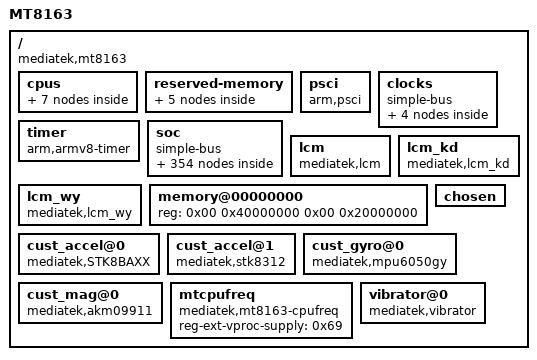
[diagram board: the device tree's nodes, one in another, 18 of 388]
/dts-v1/;

/ {
	model = "MT8163";
	compatible = "mediatek,mt8163";
	interrupt-parent = < 0x01 >;
	#address-cells = < 0x02 >;
	#size-cells = < 0x02 >;

	cpus {
		#address-cells = < 0x01 >;
		#size-cells = < 0x00 >;

		cpu@0 {
			device_type = "cpu";
			compatible = "arm,cortex-a53";
			reg = < 0x00 >;
			enable-method = "mt-boot";
			cpu-idle-states = < 0x02 0x02 0x03 0x03 0x03 >;
			cpu-release-addr = < 0x00 0x40000200 >;
			clock-frequency = "M|m";
		};

		cpu@1 {
			device_type = "cpu";
			compatible = "arm,cortex-a53";
			reg = < 0x01 >;
			enable-method = "mt-boot";
			cpu-idle-states = < 0x02 0x02 0x03 0x03 0x03 >;
			cpu-release-addr = < 0x00 0x40000200 >;
			clock-frequency = "M|m";
		};

		cpu@2 {
			device_type = "cpu";
			compatible = "arm,cortex-a53";
			reg = < 0x02 >;
			enable-method = "mt-boot";
			cpu-idle-states = < 0x02 0x02 0x03 0x03 0x03 >;
			cpu-release-addr = < 0x00 0x40000200 >;
			clock-frequency = "M|m";
		};

		cpu@3 {
			device_type = "cpu";
			compatible = "arm,cortex-a53";
			reg = < 0x03 >;
			enable-method = "mt-boot";
			cpu-idle-states = < 0x02 0x02 0x03 0x03 0x03 >;
			cpu-release-addr = < 0x00 0x40000200 >;
			clock-frequency = "M|m";
		};

		idle-states {
			entry-method = "arm,psci";

			cpu-sleep-0-0 {
				compatible = "arm,idle-state";
				arm,psci-suspend-param = < 0x10000 >;
				entry-latency-us = < 0x258 >;
				exit-latency-us = < 0x258 >;
				min-residency-us = < 0x4b0 >;
				linux,phandle = < 0x03 >;
				phandle = < 0x03 >;
			};

			cluster-sleep-0 {
				compatible = "arm,idle-state";
				arm,psci-suspend-param = < 0x2010000 >;
				entry-latency-us = < 0x320 >;
				exit-latency-us = < 0x3e8 >;
				min-residency-us = < 0x7d0 >;
				linux,phandle = < 0x02 >;
				phandle = < 0x02 >;
			};
		};
	};

	reserved-memory {
		#address-cells = < 0x02 >;
		#size-cells = < 0x02 >;
		ranges;

		atf-reserved-memory@43000000 {
			compatible = "mediatek,mt8163-atf-reserved-memory";
			no-map;
			reg = < 0x00 0x43000000 0x00 0x30000 >;
		};

		ram_console-reserved-memory@44400000 {
			compatible = "mediatek,ram_console";
			reg = < 0x00 0x44400000 0x00 0x10000 >;
		};

		pstore-reserved-memory@44410000 {
			compatible = "mediatek,pstore";
			reg = < 0x00 0x44410000 0x00 0xe0000 >;
		};

		minirdump-reserved-memory@444f0000 {
			compatible = "mediatek,minirdump";
			reg = < 0x00 0x444f0000 0x00 0x10000 >;
		};

		consys-reserve-memory {
			compatible = "mediatek,consys-reserve-memory";
			no-map;
			size = < 0x00 0x200000 >;
			alignment = < 0x00 0x200000 >;
		};
	};

	psci {
		compatible = "arm,psci";
		method = "smc";
		cpu_suspend = < 0x84000001 >;
		cpu_off = < 0x84000002 >;
		cpu_on = < 0x84000003 >;
		affinity_info = < 0x84000004 >;
	};

	clocks {
		#address-cells = < 0x02 >;
		#size-cells = < 0x02 >;
		compatible = "simple-bus";
		ranges;

		clk_null {
			compatible = "fixed-clock";
			#clock-cells = < 0x00 >;
			clock-frequency = < 0x00 >;
			linux,phandle = < 0x35 >;
			phandle = < 0x35 >;
		};

		clk26m {
			compatible = "fixed-clock";
			#clock-cells = < 0x00 >;
			clock-frequency = < 0x18cba80 >;
			linux,phandle = < 0x09 >;
			phandle = < 0x09 >;
		};

		clk32k {
			compatible = "fixed-clock";
			#clock-cells = < 0x00 >;
			clock-frequency = < 0x7d00 >;
		};

		dummy26m {
			compatible = "fixed-clock";
			clock-frequency = < 0x18cba80 >;
			#clock-cells = < 0x00 >;
		};
	};

	timer {
		compatible = "arm,armv8-timer";
		interrupt-parent = < 0x04 >;
		interrupts = < 0x01 0x0d 0xf08 0x01 0x0e 0xf08 0x01 0x0b 0xf08 0x01 0x0a 0xf08 >;
		clock-frequency = < 0xc65d40 >;
	};

	soc {
		#address-cells = < 0x02 >;
		#size-cells = < 0x02 >;
		compatible = "simple-bus";
		ranges;

		chipid@08000000 {
			compatible = "mediatek,mt8163-chipid";
			reg = < 0x00 0x8000000 0x00 0x10 >;
		};

		topckgen@10000000 {
			compatible = "mediatek,mt8163-topckgen";
			reg = < 0x00 0x10000000 0x00 0x1000 >;
			#clock-cells = < 0x01 >;
			linux,phandle = < 0x06 >;
			phandle = < 0x06 >;
		};

		infracfg@10001000 {
			compatible = "mediatek,mt8163-infracfg\0syscon";
			reg = < 0x00 0x10001000 0x00 0x1000 >;
			#clock-cells = < 0x01 >;
			#reset-cells = < 0x01 >;
			linux,phandle = < 0x05 >;
			phandle = < 0x05 >;
		};

		syscfg_pctl_a@10005000 {
			compatible = "mediatek,mt8163-pctl-a-syscfg\0syscon";
			reg = < 0x00 0x10005000 0x00 0x1000 >;
			linux,phandle = < 0x07 >;
			phandle = < 0x07 >;
		};

		toprgu@10007000 {
			compatible = "mediatek,mt8163-rgu";
			reg = < 0x00 0x10007000 0x00 0x1000 >;
			interrupts = < 0x00 0x80 0x02 >;
			#reset-cells = < 0x01 >;
			linux,phandle = < 0x50 >;
			phandle = < 0x50 >;
		};

		apxgpt@10008000 {
			compatible = "mediatek,mt8163-apxgpt";
			reg = < 0x00 0x10008000 0x00 0x1000 >;
			interrupts = < 0x00 0x98 0x08 >;
			clocks = < 0x05 0x06 0x05 0x46 0x06 0x60 >;
			clock-names = "bus\0clk13m\0rtc_sel";
		};

		pinctrl@10005000 {
			compatible = "mediatek,mt8163-pinctrl";
			reg = < 0x00 0x1000b000 0x00 0x1000 >;
			mediatek,pctl-regmap = < 0x07 >;
			pins-are-numbered;
			gpio-controller;
			#gpio-cells = < 0x02 >;
			interrupt-controller;
			#interrupt-cells = < 0x02 >;
			interrupts = < 0x00 0x99 0x04 0x00 0x9a 0x04 0x00 0x9b 0x04 >;
			pinctrl-names = "default";
			pinctrl-0 = < 0x08 >;
			linux,phandle = < 0x0a >;
			phandle = < 0x0a >;

			spi1 {
				linux,phandle = < 0x23 >;
				phandle = < 0x23 >;

				pins_spi {
					pinmux = < 0x3501 0x3601 0x3701 0x3801 >;
					bias-disable;
				};
			};

			uart0gpiodefault {
				linux,phandle = < 0x0c >;
				phandle = < 0x0c >;
			};

			uart0_rx_set {
				linux,phandle = < 0x0d >;
				phandle = < 0x0d >;

				pins_cmd_dat {
					pinmux = < 0x4f01 >;
				};
			};

			uart0_rx_clear {
				linux,phandle = < 0x0e >;
				phandle = < 0x0e >;

				pins_cmd_dat {
					pinmux = < 0x4f00 >;
					slew-rate = < 0x01 >;
					output-high;
				};
			};

			uart0_tx_set {
				linux,phandle = < 0x0f >;
				phandle = < 0x0f >;

				pins_cmd_dat {
					pinmux = < 0x5001 >;
				};
			};

			uart0_tx_clear {
				linux,phandle = < 0x10 >;
				phandle = < 0x10 >;

				pins_cmd_dat {
					pinmux = < 0x5000 >;
					slew-rate = < 0x01 >;
					output-high;
				};
			};

			uart1gpiodefault {
				linux,phandle = < 0x11 >;
				phandle = < 0x11 >;
			};

			uart1_rx_set {
				linux,phandle = < 0x12 >;
				phandle = < 0x12 >;

				pins_cmd_dat {
					pinmux = < 0x5101 >;
				};
			};

			uart1_rx_clear {
				linux,phandle = < 0x13 >;
				phandle = < 0x13 >;

				pins_cmd_dat {
					pinmux = < 0x5100 >;
					slew-rate = < 0x01 >;
					output-high;
				};
			};

			uart1_tx_set {
				linux,phandle = < 0x14 >;
				phandle = < 0x14 >;

				pins_cmd_dat {
					pinmux = < 0x5201 >;
				};
			};

			uart1_tx_clear {
				linux,phandle = < 0x15 >;
				phandle = < 0x15 >;

				pins_cmd_dat {
					pinmux = < 0x5200 >;
					slew-rate = < 0x01 >;
					output-high;
				};
			};

			uart2gpiodefault {
				linux,phandle = < 0x16 >;
				phandle = < 0x16 >;
			};

			uart2_rx_set {
				linux,phandle = < 0x17 >;
				phandle = < 0x17 >;

				pins_cmd_dat {
					pinmux = < 0xe01 >;
				};
			};

			uart2_rx_clear {
				linux,phandle = < 0x18 >;
				phandle = < 0x18 >;

				pins_cmd_dat {
					pinmux = < 0xe00 >;
					slew-rate = < 0x01 >;
					output-high;
				};
			};

			uart2_tx_set {
				linux,phandle = < 0x19 >;
				phandle = < 0x19 >;

				pins_cmd_dat {
					pins = < 0xf01 >;
				};
			};

			uart2_tx_clear {
				linux,phandle = < 0x1a >;
				phandle = < 0x1a >;

				pins_cmd_dat {
					pinmux = < 0xf00 >;
					slew-rate = < 0x01 >;
					output-high;
				};
			};

			uart3gpiodefault {
				linux,phandle = < 0x1b >;
				phandle = < 0x1b >;
			};

			uart3_rx_set {
				linux,phandle = < 0x1c >;
				phandle = < 0x1c >;

				pins_cmd_dat {
					pinmux = < 0x1001 >;
				};
			};

			uart3_rx_clear {
				linux,phandle = < 0x1d >;
				phandle = < 0x1d >;

				pins_cmd_dat {
					pinmux = < 0x1000 >;
					slew-rate = < 0x01 >;
					output-high;
				};
			};

			uart3_tx_set {
				linux,phandle = < 0x1e >;
				phandle = < 0x1e >;

				pins_cmd_dat {
					pinmux = < 0x1101 >;
				};
			};

			uart3_tx_clear {
				linux,phandle = < 0x1f >;
				phandle = < 0x1f >;

				pins_cmd_dat {
					pinmux = < 0x1100 >;
					slew-rate = < 0x01 >;
					output-high;
				};
			};

			pinconf_default {
				linux,phandle = < 0x08 >;
				phandle = < 0x08 >;
			};

			audiodefault {
				linux,phandle = < 0x2e >;
				phandle = < 0x2e >;
			};

			eint4default {
				linux,phandle = < 0x59 >;
				phandle = < 0x59 >;
			};

			eint45 {
				linux,phandle = < 0x5a >;
				phandle = < 0x5a >;

				pins_cmd_dat {
					pins = < 0x2200 >;
					bias-disable;
				};
			};

			audexamphigh {
				linux,phandle = < 0x33 >;
				phandle = < 0x33 >;

				pins_cmd_dat {
					pins = < 0x5800 >;
					slew-rate = < 0x01 >;
					output-high;
				};
			};

			audexamplow {
				linux,phandle = < 0x34 >;
				phandle = < 0x34 >;

				pins_cmd_dat {
					pins = < 0x5800 >;
					slew-rate = < 0x01 >;
					output-low;
				};
			};

			audi2s1mode0 {
				linux,phandle = < 0x31 >;
				phandle = < 0x31 >;

				pins_cmd0_dat {
					pins = < 0x2e00 >;
				};

				pins_cmd1_dat {
					pins = < 0x2f00 >;
				};

				pins_cmd2_dat {
					pins = < 0x3000 >;
				};
			};

			audi2s1mode1 {
				linux,phandle = < 0x32 >;
				phandle = < 0x32 >;

				pins_cmd0_dat {
					pins = < 0x2e02 >;
				};

				pins_cmd1_dat {
					pins = < 0x2f02 >;
				};

				pins_cmd2_dat {
					pins = < 0x3002 >;
				};
			};

			pmicclkmode0 {
				linux,phandle = < 0x2f >;
				phandle = < 0x2f >;

				pins_cmd0_dat {
					pins = < 0x700 >;
				};

				pins_cmd1_dat {
					pins = < 0x800 >;
				};

				pins_cmd2_dat {
					pins = < 0x901 >;
				};
			};

			pmicclkmode1 {
				linux,phandle = < 0x30 >;
				phandle = < 0x30 >;

				pins_cmd0_dat {
					pins = < 0x701 >;
				};

				pins_cmd1_dat {
					pins = < 0x801 >;
				};

				pins_cmd2_dat {
					pins = < 0x901 >;
				};
			};

			cam0@0 {
				linux,phandle = < 0x48 >;
				phandle = < 0x48 >;

				pins_cmd_dat {
					pins = < 0x3500 >;
					slew-rate = < 0x01 >;
					output-low;
				};
			};

			cam0@1 {
				linux,phandle = < 0x49 >;
				phandle = < 0x49 >;

				pins_cmd_dat {
					pins = < 0x3500 >;
					slew-rate = < 0x01 >;
					output-high;
				};
			};

			cam0@2 {
				linux,phandle = < 0x4a >;
				phandle = < 0x4a >;

				pins_cmd_dat {
					pins = < 0x3800 >;
					slew-rate = < 0x01 >;
					output-low;
				};
			};

			cam0@3 {
				linux,phandle = < 0x4b >;
				phandle = < 0x4b >;

				pins_cmd_dat {
					pins = < 0x3800 >;
					slew-rate = < 0x01 >;
					output-high;
				};
			};

			cam1@0 {
				linux,phandle = < 0x4c >;
				phandle = < 0x4c >;

				pins_cmd_dat {
					pins = < 0x3500 >;
					slew-rate = < 0x01 >;
					output-low;
				};
			};

			cam1@1 {
				linux,phandle = < 0x4d >;
				phandle = < 0x4d >;

				pins_cmd_dat {
					pins = < 0x3500 >;
					slew-rate = < 0x01 >;
					output-high;
				};
			};

			cam1@2 {
				linux,phandle = < 0x4e >;
				phandle = < 0x4e >;

				pins_cmd_dat {
					pins = < 0x3600 >;
					slew-rate = < 0x01 >;
					output-low;
				};
			};

			cam1@3 {
				linux,phandle = < 0x4f >;
				phandle = < 0x4f >;

				pins_cmd_dat {
					pins = < 0x3600 >;
					slew-rate = < 0x01 >;
					output-high;
				};
			};

			camdefault {
				linux,phandle = < 0x47 >;
				phandle = < 0x47 >;

				pins_cmd_dat {
					pinmux = < 0x7701 0x6a01 0x6901 0x6701 0x6801 0x6601 0x6501 0x7001 0x6f01 0x7301 0x7401 >;
				};
			};

			default {
				linux,phandle = < 0x51 >;
				phandle = < 0x51 >;
			};

			eint0default {
				linux,phandle = < 0x5c >;
				phandle = < 0x5c >;

				pins_cmd_dat {
					pins = < 0x3300 >;
					slew-rate = < 0x00 >;
					bias-disable;
				};
			};

			eint@0 {
				linux,phandle = < 0x5d >;
				phandle = < 0x5d >;

				pins_cmd_dat {
					pins = < 0x2300 >;
					slew-rate = < 0x00 >;
					bias-disable;
				};
			};

			eintoutput0 {
				linux,phandle = < 0x5e >;
				phandle = < 0x5e >;

				pins_cmd_dat {
					pins = < 0x2300 >;
					slew-rate = < 0x01 >;
					output-low;
				};
			};

			eintoutput1 {
				linux,phandle = < 0x5f >;
				phandle = < 0x5f >;

				pins_cmd_dat {
					pins = < 0x2300 >;
					slew-rate = < 0x01 >;
					output-high;
				};
			};

			rstoutput0 {
				linux,phandle = < 0x60 >;
				phandle = < 0x60 >;

				pins_cmd_dat {
					pins = < 0x2d00 >;
					slew-rate = < 0x01 >;
					output-low;
				};
			};

			rstoutput1 {
				linux,phandle = < 0x61 >;
				phandle = < 0x61 >;

				pins_cmd_dat {
					pins = < 0x2d00 >;
					slew-rate = < 0x01 >;
					output-high;
				};
			};

			iddig_irq_init {
				linux,phandle = < 0x26 >;
				phandle = < 0x26 >;

				pins_cmd_dat {
					pins = < 0x2600 >;
					slew-rate = < 0x00 >;
					bias-pull-up = < 0x00 >;
				};
			};

			drvvbus_init {
				linux,phandle = < 0x27 >;
				phandle = < 0x27 >;

				pins_cmd_dat {
					pins = < 0x2300 >;
					slew-rate = < 0x00 >;
					bias-disable;
				};
			};

			drvvbus_low {
				linux,phandle = < 0x28 >;
				phandle = < 0x28 >;

				pins_cmd_dat {
					pins = < 0x2300 >;
					slew-rate = < 0x01 >;
					output-low;
				};
			};

			drvvbus_high {
				linux,phandle = < 0x29 >;
				phandle = < 0x29 >;

				pins_cmd_dat {
					pins = < 0x2300 >;
					slew-rate = < 0x01 >;
					output-high;
				};
			};

			pogo_init {
				linux,phandle = < 0x2a >;
				phandle = < 0x2a >;

				pins_cmd_dat {
					pins = < 0x1d00 >;
					slew-rate = < 0x00 >;
					bias-disable;
				};
			};

			pogo_low {
				linux,phandle = < 0x2b >;
				phandle = < 0x2b >;

				pins_cmd_dat {
					pins = < 0x1d00 >;
					slew-rate = < 0x01 >;
					output-low;
				};
			};

			pogo_high {
				linux,phandle = < 0x2c >;
				phandle = < 0x2c >;

				pins_cmd_dat {
					pins = < 0x1d00 >;
					slew-rate = < 0x01 >;
					output-high;
				};
			};

			gpslna@0 {
				linux,phandle = < 0x52 >;
				phandle = < 0x52 >;

				pins_cmd_dat {
					pinmux = < 0x7600 >;
					slew-rate = < 0x00 >;
					bias-disable;
					output-low;
				};
			};

			gpslna@1 {
				linux,phandle = < 0x53 >;
				phandle = < 0x53 >;

				pins_cmd_dat {
					pinmux = < 0x7600 >;
					slew-rate = < 0x01 >;
					output-high;
				};
			};

			gpslna@2 {
				linux,phandle = < 0x54 >;
				phandle = < 0x54 >;

				pins_cmd_dat {
					pinmux = < 0x7600 >;
					slew-rate = < 0x01 >;
					output-low;
				};
			};

			hdmi_pins_default {
				linux,phandle = < 0x3e >;
				phandle = < 0x3e >;

				pins_cmd_dat {
					pins = < 0x5900 >;
					slew-rate = < 0x01 >;
					bias-pull-up;
					output-high;
				};
			};

			i2c0@0 {
				linux,phandle = < 0x20 >;
				phandle = < 0x20 >;

				pins1 {
					pinmux = < 0x4b01 0x4c01 >;
					bias-disable;
				};
			};

			i2c1@0 {
				linux,phandle = < 0x21 >;
				phandle = < 0x21 >;

				pins1 {
					pinmux = < 0x3901 0x3a01 >;
					bias-disable;
				};
			};

			i2c2@0 {
				linux,phandle = < 0x22 >;
				phandle = < 0x22 >;

				pins1 {
					pinmux = < 0x4d01 0x4e01 >;
					bias-disable;
				};
			};

			lcm_gpio@83_high {
				linux,phandle = < 0x62 >;
				phandle = < 0x62 >;

				pins_cmd_dat {
					pins = < 0x5300 >;
					slew-rate = < 0x01 >;
					output-high;
				};
			};

			lcm_gpio@83_low {
				linux,phandle = < 0x63 >;
				phandle = < 0x63 >;

				pins_cmd_dat {
					pins = < 0x5300 >;
					slew-rate = < 0x01 >;
					output-low;
				};
			};

			lcm_gpio@90_high {
				linux,phandle = < 0x64 >;
				phandle = < 0x64 >;

				pins_cmd_dat {
					pins = < 0x5a00 >;
					slew-rate = < 0x01 >;
					output-high;
				};
			};

			lcm_gpio@90_low {
				linux,phandle = < 0x65 >;
				phandle = < 0x65 >;

				pins_cmd_dat {
					pins = < 0x5a00 >;
					slew-rate = < 0x01 >;
					output-low;
				};
			};

			mmc0default {
				linux,phandle = < 0x36 >;
				phandle = < 0x36 >;

				pins_cmd_dat {
					pinmux = < 0x8901 0x8801 0x8701 0x8601 0x8201 0x8101 0x8001 0x7f01 0x8401 >;
					input-enable;
					bias-pull-up;
				};

				pins_clk {
					pinmux = < 0x8501 >;
					bias-pull-down;
				};

				pins_rst {
					pinmux = < 0x8301 >;
					bias-pull-up;
				};
			};

			mmc0@0 {
				linux,phandle = < 0x37 >;
				phandle = < 0x37 >;

				pins_cmd_dat {
					pinmux = < 0x8901 0x8801 0x8701 0x8601 0x8201 0x8101 0x8001 0x7f01 0x8401 >;
					input-enable;
					drive-strength = < 0x06 >;
					bias-pull-up = < 0x65 >;
				};

				pins_clk {
					pinmux = < 0x8501 >;
					drive-strength = < 0x06 >;
					bias-pull-down = < 0x65 >;
				};

				pins_rst {
					pinmux = < 0x8301 >;
					bias-pull-up;
				};
			};

			mmc1default {
				linux,phandle = < 0x3a >;
				phandle = < 0x3a >;

				pins_cmd_dat {
					pinmux = < 0x7b01 0x7c01 0x7d01 0x7e01 0x7901 >;
					input-enable;
					drive-strength = < 0x08 >;
					bias-pull-up = < 0x66 >;
				};

				pins_clk {
					pinmux = < 0x7a01 >;
					bias-pull-down;
					drive-strength = < 0x08 >;
				};

				pins_insert {
					pinmux = < 0x3700 >;
					bias-pull-up;
				};
			};

			mmc1@0 {
				linux,phandle = < 0x3b >;
				phandle = < 0x3b >;

				pins_cmd_dat {
					pinmux = < 0x7b01 0x7c01 0x7d01 0x7e01 0x7901 >;
					input-enable;
					drive-strength = < 0x04 >;
					bias-pull-up = < 0x66 >;
				};

				pins_clk {
					pinmux = < 0x7a01 >;
					drive-strength = < 0x04 >;
					bias-pull-down = < 0x66 >;
				};
			};
		};

		dramco@10004000 {
			compatible = "mediatek,mt8163-dramco";
			reg = < 0x00 0x10004000 0x00 0x1000 >;
		};

		scpsys@10006000 {
			compatible = "mediatek,mt8163-scpsys\0syscon";
			#power-domain-cells = < 0x01 >;
			reg = < 0x00 0x10006000 0x00 0x1000 >;
			interrupts = < 0x00 0xa3 0x08 0x00 0xa4 0x08 0x00 0xa5 0x08 0x00 0xa6 0x08 0x00 0xa7 0x08 0x00 0xa8 0x08 0x00 0xa9 0x08 0x00 0xaa 0x08 >;
			infracfg = < 0x05 >;
			clocks = < 0x09 0x06 0x43 >;
			clock-names = "mfg\0mm";
			linux,phandle = < 0x2d >;
			phandle = < 0x2d >;
		};

		hacc@1000a000 {
			compatible = "mediatek,hacc";
			reg = < 0x00 0x1000a000 0x00 0x1000 >;
			clocks = < 0x05 0x05 >;
			clock-names = "main";
		};

		apmixedsys@1000c000 {
			compatible = "mediatek,mt8163-apmixedsys";
			reg = < 0x00 0x1000c000 0x00 0x1000 >;
			#clock-cells = < 0x01 >;
			linux,phandle = < 0x24 >;
			phandle = < 0x24 >;
		};

		fhctl@1000cf00 {
			compatible = "mediatek,mt8163-fhctl";
			reg = < 0x00 0x1000cf00 0x00 0x100 >;
		};

		pwrap@0x1000d000 {
			compatible = "mediatek,mt8163-pwrap";
			reg = < 0x00 0x1000d000 0x00 0x1000 >;
			reg-names = "pwrap-base";
			interrupts = < 0x00 0xa1 0x04 >;
			clocks = < 0x06 0x51 0x05 0x01 >;
			clock-names = "spi\0pwrap";

			mt6323 {
				compatible = "mediatek,mt6323";

				pmicmt6323 {
					compatible = "mediatek,mt6323-pmic";
					interrupt-parent = < 0x0a >;
					interrupts = < 0x18 0x04 >;
				};

				regulators {
					compatible = "mediatek,mt6323-regulator";

					buck_vproc {
						regulator-name = "vproc";
						regulator-min-microvolt = < 0xaae60 >;
						regulator-max-microvolt = < 0x149970 >;
						regulator-ramp-delay = < 0x30d4 >;
						regulator-always-on;
						regulator-boot-on;
					};

					buck_vsys {
						regulator-name = "vsys";
						regulator-min-microvolt = < 0x155cc0 >;
						regulator-max-microvolt = < 0x2d95ec >;
						regulator-ramp-delay = < 0x61a8 >;
						regulator-always-on;
						regulator-boot-on;
					};

					buck_vpa {
						regulator-name = "vpa";
						regulator-min-microvolt = < 0x7a120 >;
						regulator-max-microvolt = < 0x37b1d0 >;
						linux,phandle = < 0x67 >;
						phandle = < 0x67 >;
					};

					ldo_vtcxo {
						regulator-name = "vtcxo";
						regulator-min-microvolt = < 0x2ab980 >;
						regulator-max-microvolt = < 0x2ab980 >;
						regulator-enable-ramp-delay = < 0x5a >;
						regulator-always-on;
						regulator-boot-on;
					};

					ldo_vcn28 {
						regulator-name = "vcn28";
						regulator-min-microvolt = < 0x2ab980 >;
						regulator-max-microvolt = < 0x2ab980 >;
						regulator-enable-ramp-delay = < 0xb9 >;
						linux,phandle = < 0x56 >;
						phandle = < 0x56 >;
					};

					ldo_vcn33_bt {
						regulator-name = "vcn33_bt";
						regulator-min-microvolt = < 0x325aa0 >;
						regulator-max-microvolt = < 0x36ee80 >;
						regulator-enable-ramp-delay = < 0xb9 >;
						linux,phandle = < 0x57 >;
						phandle = < 0x57 >;
					};

					ldo_vcn33_wifi {
						regulator-name = "vcn33_wifi";
						regulator-min-microvolt = < 0x325aa0 >;
						regulator-max-microvolt = < 0x36ee80 >;
						regulator-enable-ramp-delay = < 0xb9 >;
						linux,phandle = < 0x58 >;
						phandle = < 0x58 >;
					};

					ldo_va {
						regulator-name = "va";
						regulator-min-microvolt = < 0x2ab980 >;
						regulator-max-microvolt = < 0x2ab980 >;
						regulator-enable-ramp-delay = < 0xd8 >;
						regulator-always-on;
						regulator-boot-on;
					};

					ldo_vcama {
						regulator-name = "vcama";
						regulator-min-microvolt = < 0x16e360 >;
						regulator-max-microvolt = < 0x2ab980 >;
						regulator-enable-ramp-delay = < 0xd8 >;
						linux,phandle = < 0x43 >;
						phandle = < 0x43 >;
					};

					ldo_vio28 {
						regulator-name = "vio28";
						regulator-min-microvolt = < 0x2ab980 >;
						regulator-max-microvolt = < 0x2ab980 >;
						regulator-enable-ramp-delay = < 0xd8 >;
						regulator-always-on;
						regulator-boot-on;
					};

					ldo_vusb {
						regulator-name = "vusb";
						regulator-min-microvolt = < 0x325aa0 >;
						regulator-max-microvolt = < 0x325aa0 >;
						regulator-enable-ramp-delay = < 0xd8 >;
						regulator-boot-on;
						linux,phandle = < 0x25 >;
						phandle = < 0x25 >;
					};

					ldo_vmc {
						regulator-name = "vmc";
						regulator-min-microvolt = < 0x1b7740 >;
						regulator-max-microvolt = < 0x325aa0 >;
						regulator-enable-ramp-delay = < 0x24 >;
						regulator-boot-on;
						linux,phandle = < 0x3d >;
						phandle = < 0x3d >;
					};

					ldo_vmch {
						regulator-name = "vmch";
						regulator-min-microvolt = < 0x2dc6c0 >;
						regulator-max-microvolt = < 0x325aa0 >;
						regulator-enable-ramp-delay = < 0x24 >;
						regulator-boot-on;
						linux,phandle = < 0x3c >;
						phandle = < 0x3c >;
					};

					ldo_vemc3v3 {
						regulator-name = "vemc3v3";
						regulator-min-microvolt = < 0x2dc6c0 >;
						regulator-max-microvolt = < 0x325aa0 >;
						regulator-enable-ramp-delay = < 0x24 >;
						regulator-boot-on;
						linux,phandle = < 0x38 >;
						phandle = < 0x38 >;
					};

					ldo_vgp1 {
						regulator-name = "vgp1";
						regulator-min-microvolt = < 0x124f80 >;
						regulator-max-microvolt = < 0x325aa0 >;
						regulator-enable-ramp-delay = < 0xd8 >;
						linux,phandle = < 0x66 >;
						phandle = < 0x66 >;
					};

					ldo_vgp2 {
						regulator-name = "vgp2";
						regulator-min-microvolt = < 0x124f80 >;
						regulator-max-microvolt = < 0x2dc6c0 >;
						regulator-enable-ramp-delay = < 0xd8 >;
						linux,phandle = < 0x5b >;
						phandle = < 0x5b >;
					};

					ldo_vgp3 {
						regulator-name = "vgp3";
						regulator-min-microvolt = < 0x124f80 >;
						regulator-max-microvolt = < 0x1b7740 >;
						regulator-enable-ramp-delay = < 0xd8 >;
					};

					ldo_vcn18 {
						regulator-name = "vcn18";
						regulator-min-microvolt = < 0x1b7740 >;
						regulator-max-microvolt = < 0x1b7740 >;
						regulator-enable-ramp-delay = < 0xd8 >;
						linux,phandle = < 0x55 >;
						phandle = < 0x55 >;
					};

					ldo_vsim1 {
						regulator-name = "vsim1";
						regulator-min-microvolt = < 0x1b7740 >;
						regulator-max-microvolt = < 0x2dc6c0 >;
						regulator-enable-ramp-delay = < 0xd8 >;
					};

					ldo_vsim2 {
						regulator-name = "vsim2";
						regulator-min-microvolt = < 0x1b7740 >;
						regulator-max-microvolt = < 0x2dc6c0 >;
						regulator-enable-ramp-delay = < 0xd8 >;
					};

					ldo_vrtc {
						regulator-name = "vrtc";
						regulator-min-microvolt = < 0x2ab980 >;
						regulator-max-microvolt = < 0x2ab980 >;
						regulator-always-on;
						regulator-boot-on;
					};

					ldo_vcamaf {
						regulator-name = "vcamaf";
						regulator-min-microvolt = < 0x124f80 >;
						regulator-max-microvolt = < 0x325aa0 >;
						regulator-enable-ramp-delay = < 0xd8 >;
						linux,phandle = < 0x46 >;
						phandle = < 0x46 >;
					};

					ldo_vibr {
						regulator-name = "vibr";
						regulator-min-microvolt = < 0x124f80 >;
						regulator-max-microvolt = < 0x325aa0 >;
						regulator-enable-ramp-delay = < 0x24 >;
						linux,phandle = < 0x68 >;
						phandle = < 0x68 >;
					};

					ldo_vrf18 {
						regulator-name = "vrf18";
						regulator-min-microvolt = < 0x1bd8e8 >;
						regulator-max-microvolt = < 0x1bd8e8 >;
						regulator-enable-ramp-delay = < 0xbb >;
					};

					ldo_vm {
						regulator-name = "vm";
						regulator-min-microvolt = < 0x124f80 >;
						regulator-max-microvolt = < 0x1b7740 >;
						regulator-enable-ramp-delay = < 0xd8 >;
						regulator-always-on;
						regulator-boot-on;
					};

					ldo_vio18 {
						regulator-name = "vio18";
						regulator-min-microvolt = < 0x1b7740 >;
						regulator-max-microvolt = < 0x1b7740 >;
						regulator-enable-ramp-delay = < 0xd8 >;
						regulator-always-on;
						regulator-boot-on;
						linux,phandle = < 0x39 >;
						phandle = < 0x39 >;
					};

					ldo_vcamd {
						regulator-name = "vcamd";
						regulator-min-microvolt = < 0x124f80 >;
						regulator-max-microvolt = < 0x1b7740 >;
						regulator-enable-ramp-delay = < 0xd8 >;
						linux,phandle = < 0x44 >;
						phandle = < 0x44 >;
					};

					ldo_vcamio {
						regulator-name = "vcamio";
						regulator-min-microvolt = < 0x1b7740 >;
						regulator-max-microvolt = < 0x1b7740 >;
						regulator-enable-ramp-delay = < 0xd8 >;
						linux,phandle = < 0x45 >;
						phandle = < 0x45 >;
					};
				};
			};
		};

		devapc_ao@1000e000 {
			compatible = "mediatek,mt8163-devapc_ao";
			reg = < 0x00 0x1000e000 0x00 0x1000 >;
		};

		ddrphy@1000f000 {
			compatible = "mediatek,mt8163-ddrphy\0mediatek,ddrphy";
			reg = < 0x00 0x1000f000 0x00 0x1000 >;
			clocks = < 0x05 0x36 >;
			clock-names = "dramc_f26m";
		};

		keypad@10010000 {
			compatible = "mediatek,mt8163-keypad";
			reg = < 0x00 0x10010000 0x00 0x1000 >;
			interrupts = < 0x00 0xa2 0x02 >;
			mediatek,kpd-key-debounce = < 0x400 >;
			mediatek,kpd-sw-pwrkey = < 0x74 >;
			mediatek,kpd-hw-pwrkey = < 0x08 >;
			mediatek,kpd-sw-rstkey = < 0x72 >;
			mediatek,kpd-hw-rstkey = < 0x11 >;
			mediatek,kpd-use-extend-type = < 0x00 >;
			mediatek,kpd-hw-map-num = < 0x48 >;
			mediatek,kpd-hw-init-map = < 0x73 0x72 0x00 0x00 0x00 0x00 0x00 0x00 0x00 0x00 0x00 0x00 0x00 0x00 0x00 0x00 0x00 0x00 0x00 0x00 0x00 0x00 0x00 0x00 0x00 0x00 0x00 0x00 0x00 0x00 0x00 0x00 0x00 0x00 0x00 0x00 0x00 0x00 0x00 0x00 0x00 0x00 0x00 0x00 0x00 0x00 0x00 0x00 0x00 0x00 0x00 0x00 0x00 0x00 0x00 0x00 0x00 0x00 0x00 0x00 0x00 0x00 0x00 0x00 0x00 0x00 0x00 0x00 0x00 0x00 0x00 0x00 >;
			mediatek,kpd-pwrkey-eint-gpio = < 0x00 >;
			mediatek,kpd-pwkey-gpio-din = < 0x00 >;
			mediatek,kpd-hw-dl-key0 = < 0x00 >;
			mediatek,kpd-hw-dl-key1 = < 0x01 >;
			mediatek,kpd-hw-dl-key2 = < 0x08 >;
			mediatek,kpd-hw-recovery-key = < 0x00 >;
			mediatek,kpd-hw-factory-key = < 0x01 >;
		};

		md32@10020000 {
			compatible = "mediatek,mt8163-md32";
			reg = < 0x00 0x10020000 0x00 0x38000 0x00 0x10058000 0x00 0x400 0x00 0x10059000 0x00 0x400 >;
			interrupts = < 0x00 0xae 0x04 >;
			clocks = < 0x05 0x04 >;
			clock-names = "sys";
			status = "okay";
		};

		mcucfg@10200000 {
			compatible = "mediatek,mt8173-mcucfg\0syscon";
			reg = < 0x00 0x10200000 0x00 0x1000 >;
		};

		cpuxgpt@10200000 {
			compatible = "mediatek,mt8163-cpuxgpt";
			interrupts = < 0x00 0x40 0x04 0x00 0x41 0x04 0x00 0x42 0x04 0x00 0x43 0x04 >;
		};

		lastpc@10200000 {
			compatible = "mediatek,mt8163-mcucfg";
			reg = < 0x00 0x10200000 0x00 0x200 >;
		};

		intpol-controller@10200620 {
			compatible = "mediatek,mt8163-sysirq\0mediatek,mt6577-sysirq";
			interrupt-controller;
			#interrupt-cells = < 0x03 >;
			interrupt-parent = < 0x04 >;
			reg = < 0x00 0x10200620 0x00 0x20 >;
			linux,phandle = < 0x01 >;
			phandle = < 0x01 >;
		};

		emi@10203000 {
			compatible = "mediatek,mt8163-emi\0mediatek,emi";
			reg = < 0x00 0x10203000 0x00 0x1000 >;
			interrupts = < 0x00 0x85 0x04 >;
		};

		sys_cirq@10204000 {
			compatible = "mediatek,mt8163-sys_cirq\0mediatek,mt6735-sys_cirq";
			reg = < 0x00 0x10204000 0x00 0x1000 >;
			interrupts = < 0x00 0xf0 0x08 >;
			mediatek,cirq_num = < 0xa9 >;
			mediatek,spi_start_offset = < 0x48 >;
		};

		m4u@10205000 {
			cell-index = < 0x00 >;
			compatible = "mediatek,mt8163-m4u";
			reg = < 0x00 0x10205000 0x00 0x1000 >;
			interrupts = < 0x00 0x93 0x08 >;
		};

		devapc@10207000 {
			compatible = "mediatek,mt8163-devapc";
			reg = < 0x00 0x10207000 0x00 0x1000 >;
			interrupts = < 0x00 0x85 0x08 >;
			clocks = < 0x05 0x2b >;
			clock-names = "main";
		};

		systracker@10208000 {
			compatible = "mediatek,bus_dbg-v1";
			reg = < 0x00 0x10208000 0x00 0x1000 >;
			interrupts = < 0x00 0x84 0x08 >;
		};

		dramc_nao@1020e000 {
			compatible = "mediatek,mt8163-dramc_nao\0mediatek,dramc_nao";
			reg = < 0x00 0x1020e000 0x00 0x1000 >;
		};

		gcpu@10210000 {
			compatible = "mediatek,mt8163-gcpu";
			reg = < 0x00 0x10210000 0x00 0x1000 >;
			clocks = < 0x05 0x20 >;
			clock-names = "main";
		};

		gce@10212000 {
			compatible = "mediatek,mt8163-gce";
			reg = < 0x00 0x10212000 0x00 0x1000 >;
			interrupts = < 0x00 0x8f 0x08 0x00 0x90 0x08 >;
			clocks = < 0x05 0x09 0x0b 0x00 0x0b 0x01 0x0b 0x02 0x0b 0x03 0x0b 0x04 0x0b 0x05 0x0b 0x06 0x0b 0x08 0x0b 0x07 >;
			clock-names = "MT_CG_INFRA_GCE\0MT_CG_DISP0_SMI_COMMON\0MT_CG_DISP0_SMI_LARB0\0MT_CG_DISP0_CAM_MDP\0MT_CG_DISP0_MDP_RDMA0\0MT_CG_DISP0_MDP_RSZ0\0MT_CG_DISP0_MDP_RSZ1\0MT_CG_DISP0_MDP_TDSHP0\0MT_CG_DISP0_MDP_WROT0\0MT_CG_DISP0_MDP_WDMA";
		};

		perisys_iommu@10214000 {
			cell-index = < 0x01 >;
			compatible = "mediatek,mt8163-perisys_iommu";
			reg = < 0x00 0x10214000 0x00 0x1000 >;
			interrupts = < 0x00 0x91 0x08 >;
		};

		interrupt-controller@10221000 {
			compatible = "arm,gic-400";
			interrupt-controller;
			#interrupt-cells = < 0x03 >;
			interrupt-parent = < 0x04 >;
			reg = < 0x00 0x10221000 0x00 0x1000 0x00 0x10222000 0x00 0x1000 0x00 0x10224000 0x00 0x2000 0x00 0x10226000 0x00 0x2000 >;
			interrupts = < 0x01 0x09 0xf04 >;
			linux,phandle = < 0x04 >;
			phandle = < 0x04 >;
		};

		btif_tx@11000700 {
			compatible = "mediatek,btif_tx";
			reg = < 0x00 0x11000700 0x00 0x80 >;
			interrupts = < 0x00 0x6e 0x08 >;
		};

		btif_rx@11000780 {
			compatible = "mediatek,btif_rx";
			reg = < 0x00 0x11000780 0x00 0x80 >;
			interrupts = < 0x00 0x6f 0x08 >;
		};

		auxadc@11001000 {
			compatible = "mediatek,mt8163-auxadc\0mediatek,mt6735-auxadc";
			reg = < 0x00 0x11001000 0x00 0x1000 >;
			interrupts = < 0x00 0x4c 0x02 >;
			clocks = < 0x05 0x21 >;
			clock-names = "auxadc-main";
		};

		uart0@11002000 {
			cell-index = < 0x00 >;
			compatible = "mediatek,mt8163-uart";
			reg = < 0x00 0x11002000 0x00 0x1000 0x00 0x11000300 0x00 0x1000 0x00 0x11000380 0x00 0x80 >;
			interrupts = < 0x00 0x5b 0x08 0x00 0x66 0x08 0x00 0x67 0x08 >;
			clock-frequency = < 0x18cba80 >;
			clock-div = < 0x01 >;
			clocks = < 0x05 0x13 0x05 0x29 >;
			clock-names = "uart0-main\0uart-apdma";
			pinctrl-names = "uart0_gpio_default\0uart0_rx_set\0uart0_rx_clear\0uart0_tx_set\0uart0_tx_clear";
			pinctrl-0 = < 0x0c >;
			pinctrl-1 = < 0x0d >;
			pinctrl-2 = < 0x0e >;
			pinctrl-3 = < 0x0f >;
			pinctrl-4 = < 0x10 >;
			rx_gpios = < 0x0a 0x4f 0x00 >;
			tx_gpios = < 0x0a 0x50 0x00 >;
			status = "okay";
		};

		uart1@11003000 {
			cell-index = < 0x01 >;
			compatible = "mediatek,mt8163-uart";
			reg = < 0x00 0x11003000 0x00 0x1000 0x00 0x11000400 0x00 0x80 0x00 0x11000480 0x00 0x80 >;
			interrupts = < 0x00 0x5c 0x08 0x00 0x68 0x08 0x00 0x69 0x08 >;
			clock-frequency = < 0x18cba80 >;
			clock-div = < 0x01 >;
			clocks = < 0x05 0x14 >;
			clock-names = "uart1-main";
			pinctrl-names = "uart1_gpio_default\0uart1_rx_set\0uart1_rx_clear\0uart1_tx_set\0uart1_tx_clear";
			pinctrl-0 = < 0x11 >;
			pinctrl-1 = < 0x12 >;
			pinctrl-2 = < 0x13 >;
			pinctrl-3 = < 0x14 >;
			pinctrl-4 = < 0x15 >;
			rx_gpios = < 0x0a 0x51 0x00 >;
			tx_gpios = < 0x0a 0x52 0x00 >;
			status = "disable";
		};

		uart2@11004000 {
			cell-index = < 0x02 >;
			compatible = "mediatek,mt8163-uart";
			reg = < 0x00 0x11004000 0x00 0x1000 0x00 0x11000500 0x00 0x80 0x00 0x11000580 0x00 0x80 >;
			interrupts = < 0x00 0x5d 0x08 0x00 0x6a 0x08 0x00 0x6b 0x08 >;
			clock-frequency = < 0x18cba80 >;
			clock-div = < 0x01 >;
			clocks = < 0x05 0x15 >;
			clock-names = "uart2-main";
			pinctrl-names = "uart2_gpio_default\0uart2_rx_set\0uart2_rx_clear\0uart2_tx_set\0uart2_tx_clear";
			pinctrl-0 = < 0x16 >;
			pinctrl-1 = < 0x17 >;
			pinctrl-2 = < 0x18 >;
			pinctrl-3 = < 0x19 >;
			pinctrl-4 = < 0x1a >;
			rx_gpios = < 0x0a 0x0e 0x00 >;
			tx_gpios = < 0x0a 0x0f 0x00 >;
			status = "disable";
		};

		uart3@11005000 {
			cell-index = < 0x03 >;
			compatible = "mediatek,mt8163-uart";
			reg = < 0x00 0x11005000 0x00 0x1000 0x00 0x11000600 0x00 0x80 0x00 0x11000680 0x00 0x80 >;
			interrupts = < 0x00 0x5e 0x08 0x00 0x6c 0x08 0x00 0x6d 0x08 >;
			clock-frequency = < 0x18cba80 >;
			clock-div = < 0x01 >;
			clocks = < 0x05 0x16 >;
			clock-names = "uart3-main";
			pinctrl-names = "uart3_gpio_default\0uart3_rx_set\0uart3_rx_clear\0uart3_tx_set\0uart3_tx_clear";
			pinctrl-0 = < 0x1b >;
			pinctrl-1 = < 0x1c >;
			pinctrl-2 = < 0x1d >;
			pinctrl-3 = < 0x1e >;
			pinctrl-4 = < 0x1f >;
			rx_gpios = < 0x0a 0x10 0x00 >;
			tx_gpios = < 0x0a 0x11 0x00 >;
			status = "disable";
		};

		pwm@11006000 {
			compatible = "mediatek,mt8163-pwm";
			reg = < 0x00 0x11006000 0x00 0x1000 >;
			interrupts = < 0x00 0x4d 0x08 >;
			clocks = < 0x05 0x12 0x05 0x0f 0x05 0x10 0x05 0x11 >;
			clock-names = "PWM-main\0PWM1-main\0PWM2-main\0PWM3-main";
		};

		i2c@11007000 {
			compatible = "mediatek,mt8173-i2c";
			reg = < 0x00 0x11007000 0x00 0x70 0x00 0x11000180 0x00 0x80 >;
			interrupts = < 0x00 0x54 0x08 >;
			clock-div = < 0x08 >;
			clocks = < 0x05 0x0b 0x05 0x29 >;
			clock-names = "main\0dma";
			#address-cells = < 0x01 >;
			#size-cells = < 0x00 >;
			status = "okay";
			pinctrl-names = "default";
			pinctrl-0 = < 0x20 >;

			camera_main_af@0c {
				compatible = "mediatek,camera_main_af";
				reg = < 0x18 >;
			};

			lp8557_led@2c {
				compatible = "ti,lp8557-led";
				reg = < 0x2c >;
			};

			kd_camera_hw2@30 {
				compatible = "mediatek,camera_sub";
				reg = < 0x30 >;
			};

			kd_camera_hw1@36 {
				compatible = "mediatek,camera_main";
				reg = < 0x36 >;
			};

			cap_touch@40 {
				compatible = "mediatek,cap_touch";
				reg = < 0x40 >;
				interrupt-parent = < 0x0a >;
				interrupts = < 0x13 0x02 >;
				int-gpio = < 0x0a 0x33 0x00 >;
				rst-gpio = < 0x0a 0x34 0x00 >;
			};
		};

		i2c@11008000 {
			compatible = "mediatek,mt8173-i2c";
			reg = < 0x00 0x11008000 0x00 0x70 0x00 0x11000200 0x00 0x80 >;
			interrupts = < 0x00 0x55 0x08 >;
			clock-div = < 0x08 >;
			clocks = < 0x05 0x0c 0x05 0x29 >;
			clock-names = "main\0dma";
			#address-cells = < 0x01 >;
			#size-cells = < 0x00 >;
			status = "okay";
			pinctrl-names = "default";
			pinctrl-0 = < 0x21 >;

			sym827@60 {
				compatible = "silergy,sym827-regulator";
				reg = < 0x60 >;
				regulator-name = "vproc";
				regulator-min-microvolt = < 0x927c0 >;
				regulator-max-microvolt = < 0x152bec >;
				regulator-enable-ramp-delay = < 0x190 >;
				regulator-ramp-delay = < 0x208d >;
				regulator-always-on;
				vsel-gpio = < 0x0a 0x51 0x00 >;
				linux,phandle = < 0x69 >;
				phandle = < 0x69 >;
			};
		};

		i2c@11009000 {
			compatible = "mediatek,mt8173-i2c";
			reg = < 0x00 0x11009000 0x00 0x70 0x00 0x11000280 0x00 0x80 >;
			interrupts = < 0x00 0x56 0x08 >;
			clock-div = < 0x0a >;
			clocks = < 0x05 0x0d 0x05 0x29 >;
			clock-names = "main\0dma";
			#address-cells = < 0x01 >;
			#size-cells = < 0x00 >;
			status = "okay";
			pinctrl-names = "default";
			pinctrl-0 = < 0x22 >;

			msensor@0c {
				compatible = "mediatek,msensor";
				reg = < 0x0c >;
				rst-gpio = < 0x0a 0x34 0x00 >;
			};

			gsensor@18 {
				compatible = "mediatek,gsensor1";
				reg = < 0x18 >;
			};

			gsensor@3d {
				compatible = "mediatek,gsensor";
				reg = < 0x3d >;
			};

			gyro@69 {
				compatible = "mediatek,gyro";
				reg = < 0x69 >;
			};

			bq24296@6b {
				compatible = "ti,bq24296";
				reg = < 0x6b >;
			};
		};

		spi@1100a000 {
			compatible = "mediatek,mt8163-spi";
			#address-cells = < 0x01 >;
			#size-cells = < 0x00 >;
			reg = < 0x00 0x1100a000 0x00 0x1000 >;
			interrupts = < 0x00 0x76 0x08 >;
			clocks = < 0x06 0x29 0x06 0x49 0x05 0x1b >;
			clock-names = "parent-clk\0sel-clk\0spi-clk";
			pinctrl-names = "default";
			pinctrl-0 = < 0x23 >;
			status = "disabled";
		};

		thermal@1100b000 {
			compatible = "mediatek,mt8163-thermal";
			reg = < 0x00 0x1100b000 0x00 0x1000 >;
			interrupts = < 0x00 0x4e 0x08 >;
			clocks = < 0x05 0x0a 0x05 0x21 >;
			clock-names = "therm\0auxadc";
			apmixedsys = < 0x24 >;
		};

		ptp_od@1100b000 {
			compatible = "mediatek,mt8163-ptp_od";
			reg = < 0x00 0x1100b000 0x00 0x1000 >;
			interrupts = < 0x00 0x7d 0x08 >;
			clocks = < 0x05 0x0a >;
			clock-names = "ptp_infra_therm";
		};

		btif@1100c000 {
			compatible = "mediatek,btif";
			reg = < 0x00 0x1100c000 0x00 0x1000 >;
			interrupts = < 0x00 0x70 0x08 >;
			clocks = < 0x05 0x1a 0x05 0x29 >;
			clock-names = "btifc\0apdmac";
		};

		nfi@1100d000 {
			compatible = "mediatek,mt8163-nfi";
			reg = < 0x00 0x1100d000 0x00 0x1000 >;
			interrupts = < 0x00 0x60 0x08 >;
			clocks = < 0x05 0x32 0x05 0x28 0x05 0x27 0x06 0x5d 0x09 0x06 0x26 0x06 0x21 0x05 0x45 0x06 0x40 0x05 0x3c 0x05 0x18 0x05 0x19 0x05 0x33 >;
			clock-names = "nfi_hclk\0nfiecc_bclk\0nfi_bclk\0onfi_sel\0onfi_clk26m\0onfi_mode5\0onfi_mode4\0nfi_bclk_sel\0nfi_ahb_clk\0nfi_1xpad_clk\0nfiecc_pclk\0nfi_pclk\0onfi_pad_clk";
		};

		nfiecc@1100e000 {
			compatible = "mediatek,mt8163-nfiecc";
			reg = < 0x00 0x1100e000 0x00 0x1000 >;
			interrupts = < 0x00 0x5f 0x08 >;
		};

		usb@11200000 {
			compatible = "mediatek,mt8163-usb20";
			reg = < 0x00 0x11200000 0x00 0x10000 0x00 0x11210000 0x00 0x10000 >;
			interrupts = < 0x00 0x48 0x08 >;
			mode = < 0x02 >;
			multipoint = < 0x01 >;
			dyn_fifo = < 0x01 >;
			soft_con = < 0x01 >;
			dma = < 0x01 >;
			num_eps = < 0x10 >;
			dma_channels = < 0x08 >;
			clocks = < 0x24 0x02 0x05 0x17 0x05 0x07 0x05 0x08 >;
			clock-names = "usbpll\0usbmcu\0usb\0icusb";
			vusb-supply = < 0x25 >;
			pinctrl-names = "iddig_irq_init\0drvvbus_init\0drvvbus_low\0drvvbus_high\0pogo_init\0pogo_low\0pogo_high";
			pinctrl-0 = < 0x26 >;
			pinctrl-1 = < 0x27 >;
			pinctrl-2 = < 0x28 >;
			pinctrl-3 = < 0x29 >;
			pinctrl-4 = < 0x2a >;
			pinctrl-5 = < 0x2b >;
			pinctrl-6 = < 0x2c >;
			iddig_gpio = < 0x0a 0x26 0x00 >;
			drvvbus_gpio = < 0x0a 0x23 0x00 >;
			pogo_gpio = < 0x0a 0x1d 0x00 >;
			status = "okay";
		};

		audiosys@11220000 {
			compatible = "mediatek,mt8163-audiosys\0syscon";
			reg = < 0x00 0x11220000 0x00 0x1000 >;
			#clock-cells = < 0x01 >;
		};

		mt_soc_dl1_pcm@11220000 {
			compatible = "mediatek,mt8163-soc-pcm-dl1";
			reg = < 0x00 0x11220000 0x00 0x1000 0x00 0x11221000 0x00 0x9000 >;
			interrupts = < 0x00 0x8e 0x08 >;
			clocks = < 0x05 0x30 0x06 0x4f 0x06 0x50 0x06 0x57 0x06 0x58 0x24 0x08 0x24 0x09 0x09 >;
			clock-names = "aud_infra_clk\0top_mux_audio\0top_mux_audio_intbus\0aud_mux1_clk\0aud_mux2_clk\0apmixed_apll1_clk\0apmixed_apll2_clk\0top_clk26m_clk";
			audclk-gpio = < 0x07 0x00 >;
			audmiso-gpio = < 0x08 0x00 >;
			audmosi-gpio = < 0x09 0x00 >;
			extspkamp-gpio = < 0x18 0x00 >;
			i2s1clk-gpio = < 0x30 0x00 >;
			i2s1dat-gpio = < 0x2e 0x00 >;
			i2s1mclk-gpio = < 0x0f 0x00 >;
			i2s1ws-gpio = < 0x2f 0x00 >;
			power-domains = < 0x2d 0x05 >;
			pinctrl-names = "default\0audpmicclk-mode0\0audpmicclk-mode1\0audi2s1-mode0\0audi2s1-mode1\0extamp-pullhigh\0extamp-pulllow";
			pinctrl-0 = < 0x2e >;
			pinctrl-1 = < 0x2f >;
			pinctrl-2 = < 0x30 >;
			pinctrl-3 = < 0x31 >;
			pinctrl-4 = < 0x32 >;
			pinctrl-5 = < 0x33 >;
			pinctrl-6 = < 0x34 >;
			status = "okay";
		};

		mt_soc_ul1_pcm@11220000 {
			compatible = "mediatek,mt8163-soc-pcm-capture";
		};

		mt_soc_voice_md1@11220000 {
			compatible = "mediatek,mt8163-soc-pcm-voice-md1";
		};

		mt_soc_hdmi_pcm@11220000 {
			compatible = "mediatek,mt8163-soc-pcm-hdmi";
		};

		mt_soc_uldlloopback@11220000 {
			compatible = "mediatek,mt8163-soc-pcm-uldlloopback";
		};

		mt_soc_i2s0_pcm@11220000 {
			compatible = "mediatek,mt8163-soc-pcm-dl1-i2s0";
		};

		mt_soc_mrgrx_pcm@11220000 {
			compatible = "mediatek,mt8163-soc-pcm-mrgrx";
		};

		mt_soc_mrgrx_awb_pcm@11220000 {
			compatible = "mediatek,mt8163-soc-pcm-mrgrx-awb";
		};

		mt_soc_fm_i2s_pcm@11220000 {
			compatible = "mediatek,mt8163-soc-pcm-fm-i2s";
		};

		mt_soc_fm_i2s_awb_pcm@11220000 {
			compatible = "mediatek,mt8163-soc-pcm-fm-i2s-awb";
		};

		mt_soc_i2s0dl1_pcm@11220000 {
			compatible = "mediatek,mt8163-soc-pcm-dl1-i2s0Dl1";
		};

		mt_soc_dl1_awb_pcm@11220000 {
			compatible = "mediatek,mt8163-soc-pcm-dl1-awb";
		};

		mt_soc_voice_md1_bt@11220000 {
			compatible = "mediatek,mt8163-soc-pcm-voice-md1-bt";
		};

		mt_soc_voip_bt_out@11220000 {
			compatible = "mediatek,mt8163-soc-pcm-dl1-bt";
		};

		mt_soc_voip_bt_in@11220000 {
			compatible = "mediatek,mt8163-soc-pcm-bt-dai";
		};

		mt_soc_tdmrx_pcm@11220000 {
			compatible = "mediatek,mt8163-soc-tdm-capture";
		};

		mt_soc_fm_mrgtx_pcm@11220000 {
			compatible = "mediatek,mt8163-soc-pcm-fmtx";
		};

		mt_soc_ul2_pcm@11220000 {
			compatible = "mediatek,mt8163-soc-pcm-capture2";
		};

		mt_soc_i2s0_awb_pcm@11220000 {
			compatible = "mediatek,mt8163-soc-pcm-i2s0-awb";
		};

		mt_soc_voice_md2@11220000 {
			compatible = "mediatek,mt8163-soc-pcm-voice-md2";
		};

		mt_soc_routing_pcm@11220000 {
			compatible = "mediatek,mt8163-soc-pcm-routing";
		};

		mt_soc_voice_md2_bt@11220000 {
			compatible = "mediatek,mt8163-soc-pcm-voice-md2-bt";
		};

		mt_soc_hp_impedance@11220000 {
			compatible = "mediatek,mt8163-soc-pcm-hp-impedance";
		};

		mt_soc_codec_name@11220000 {
			compatible = "mediatek,mt8163-soc-codec-63xx";
		};

		mt_soc_dummy_pcm@11220000 {
			compatible = "mediatek,mt8163-soc-pcm-dummy";
		};

		mt_soc_codec_dummy_name@11220000 {
			compatible = "mediatek,mt8163-soc-codec-dummy";
		};

		mt_soc_routing_dai_name@11220000 {
			compatible = "mediatek,mt8163-soc-dai-routing";
		};

		mt_soc_dai_name@11220000 {
			compatible = "mediatek,mt8163-soc-dai-stub";
		};

		mfg@13000000 {
			compatible = "mediatek,mt8163-mfg\0mediatek,midgard-mfg";
			reg = < 0x00 0x13000000 0x00 0x1000 >;
			clocks = < 0x06 0x46 0x06 0x18 >;
			clock-names = "topck\0pll";
			power-domains = < 0x2d 0x00 >;
		};

		gpu@13040000 {
			compatible = "arm,malit720\0arm,mali-t72x\0arm,malit7xx\0arm,mali-midgard";
			reg = < 0x00 0x13040000 0x00 0x4000 >;
			interrupts = < 0x00 0xe3 0x08 0x00 0xe2 0x08 0x00 0xe1 0x08 >;
			interrupt-names = "JOB\0MMU\0GPU";
			clock-frequency = < 0x1efe9200 >;
			power-domains = < 0x2d 0x07 >;
		};

		mmc@11230000 {
			compatible = "mediatek,mt8163-mmc";
			reg = < 0x00 0x11230000 0x00 0x1000 >;
			interrupts = < 0x00 0x4f 0x08 >;
			clocks = < 0x05 0x1c 0x05 0x1f 0x35 >;
			clock-names = "extra\0source\0hclk";
			status = "okay";
			pinctrl-names = "default\0state_uhs";
			pinctrl-0 = < 0x36 >;
			pinctrl-1 = < 0x37 >;
			bus-width = < 0x08 >;
			latch-ck = < 0x01 >;
			max-frequency = < 0xbebc200 >;
			cap-mmc-highspeed;
			mmc-hs200-1_8v;
			cap-mmc-hw-reset;
			vmmc-supply = < 0x38 >;
			vqmmc-supply = < 0x39 >;
			non-removable;
		};

		mmc@11240000 {
			compatible = "mediatek,mt8163-mmc";
			reg = < 0x00 0x11240000 0x00 0x1000 >;
			interrupts = < 0x00 0x50 0x08 >;
			clocks = < 0x05 0x1d 0x06 0x4b 0x35 >;
			clock-names = "sd_extra\0source\0hclk";
			status = "okay";
			pinctrl-names = "default\0state_uhs";
			pinctrl-0 = < 0x3a >;
			pinctrl-1 = < 0x3b >;
			bus-width = < 0x04 >;
			latch-ck = < 0x01 >;
			max-frequency = < 0xbebc200 >;
			cap-sd-highspeed;
			sd-uhs-sdr50;
			sd-uhs-sdr104;
			cd-gpios = < 0x0a 0x37 0x00 >;
			vmmc-supply = < 0x3c >;
			vqmmc-supply = < 0x3d >;
		};

		usb@11270000 {
			compatible = "mediatek,mt8163-usb11";
			cell-index = < 0x01 >;
			reg = < 0x00 0x11270000 0x00 0x10000 0x00 0x11210000 0x00 0x10000 >;
			interrupts = < 0x00 0x49 0x08 >;
			mode = < 0x02 >;
			multipoint = < 0x01 >;
			dyn_fifo = < 0x01 >;
			soft_con = < 0x01 >;
			dma = < 0x01 >;
			num_eps = < 0x08 >;
			dma_channels = < 0x04 >;
			status = "okay";
		};

		mmsys@14000000 {
			compatible = "mediatek,mt8163-mmsys\0syscon";
			reg = < 0x00 0x14000000 0x00 0x1000 >;
			#clock-cells = < 0x01 >;
			linux,phandle = < 0x0b >;
			phandle = < 0x0b >;
		};

		mdp_rdma@14001000 {
			compatible = "mediatek,mt8163-mdp_rdma";
			reg = < 0x00 0x14001000 0x00 0x1000 >;
			interrupts = < 0x00 0xb2 0x08 >;
		};

		mdp_rsz0@14002000 {
			compatible = "mediatek,mt8163-mdp_rsz0";
			reg = < 0x00 0x14002000 0x00 0x1000 >;
			interrupts = < 0x00 0xb3 0x08 >;
		};

		mdp_rsz1@14003000 {
			compatible = "mediatek,mt8163-mdp_rsz1";
			reg = < 0x00 0x14003000 0x00 0x1000 >;
			interrupts = < 0x00 0xb4 0x08 >;
		};

		mdp_wdma@14004000 {
			compatible = "mediatek,mt8163-mdp_wdma";
			reg = < 0x00 0x14004000 0x00 0x1000 >;
			interrupts = < 0x00 0xb6 0x08 >;
		};

		mdp_wrot@14005000 {
			compatible = "mediatek,mt8163-mdp_wrot";
			reg = < 0x00 0x14005000 0x00 0x1000 >;
			interrupts = < 0x00 0xb7 0x08 >;
		};

		mdp_tdshp@14006000 {
			compatible = "mediatek,mt8163-mdp_tdshp0";
			reg = < 0x00 0x14006000 0x00 0x1000 >;
			interrupts = < 0x00 0xb5 0x08 >;
		};

		mt8163-dispsys {
			compatible = "mediatek,mt8163-dispsys";
		};

		disp_ovl0@14007000 {
			compatible = "mediatek,mt8163-disp_ovl0";
			reg = < 0x00 0x14007000 0x00 0x1000 >;
			interrupts = < 0x00 0xb8 0x08 >;
		};

		disp_ovl1@14008000 {
			compatible = "mediatek,mt8163-disp_ovl1";
			reg = < 0x00 0x14008000 0x00 0x1000 >;
			interrupts = < 0x00 0xb9 0x08 >;
		};

		disp_rdma0@14009000 {
			compatible = "mediatek,mt8163-disp_rdma0";
			reg = < 0x00 0x14009000 0x00 0x1000 >;
			interrupts = < 0x00 0xba 0x08 >;
		};

		disp_rdma1@1400a000 {
			compatible = "mediatek,mt8163-disp_rdma1";
			reg = < 0x00 0x1400a000 0x00 0x1000 >;
			interrupts = < 0x00 0xbb 0x08 >;
		};

		disp_wdma0@1400b000 {
			compatible = "mediatek,mt8163-disp_wdma0";
			reg = < 0x00 0x1400b000 0x00 0x1000 >;
			interrupts = < 0x00 0xbc 0x08 >;
		};

		disp_color@1400c000 {
			compatible = "mediatek,mt8163-disp_color";
			reg = < 0x00 0x1400c000 0x00 0x1000 >;
			interrupts = < 0x00 0xbd 0x08 >;
		};

		disp_ccorr@1400d000 {
			compatible = "mediatek,mt8163-disp_ccorr";
			reg = < 0x00 0x1400d000 0x00 0x1000 >;
			interrupts = < 0x00 0xbe 0x08 >;
		};

		disp_aal@1400e000 {
			compatible = "mediatek,mt8163-disp_aal";
			reg = < 0x00 0x1400e000 0x00 0x1000 >;
			interrupts = < 0x00 0xbf 0x08 >;
		};

		disp_gamma@1400f000 {
			compatible = "mediatek,mt8163-disp_gamma";
			reg = < 0x00 0x1400f000 0x00 0x1000 >;
			interrupts = < 0x00 0xc0 0x08 >;
		};

		disp_dither@14010000 {
			compatible = "mediatek,mt8163-disp_dither";
			reg = < 0x00 0x14010000 0x00 0x1000 >;
			interrupts = < 0x00 0xc1 0x08 >;
		};

		disp_ufoe@14011000 {
			compatible = "mediatek,mt8163-disp_ufoe";
			reg = < 0x00 0x14011000 0x00 0x1000 >;
		};

		disp_dsi0@14012000 {
			compatible = "mediatek,mt8163-disp_dsi0";
			reg = < 0x00 0x14012000 0x00 0x1000 >;
			interrupts = < 0x00 0xc3 0x08 >;
		};

		disp_dpi0@14013000 {
			compatible = "mediatek,mt8163-disp_dpi0";
			reg = < 0x00 0x14013000 0x00 0x1000 >;
			interrupts = < 0x00 0xc4 0x08 >;
		};

		disp_dpi1@1401c000 {
			compatible = "mediatek,mt8163-disp_dpi1";
			reg = < 0x00 0x1401c000 0x00 0x1000 >;
			interrupts = < 0x00 0xc9 0x08 >;
		};

		hdmi@1401d000 {
			compatible = "mediatek,mt8163-hdmitx";
			power-domains = < 0x2d 0x00 >;
			reg = < 0x00 0x1401d000 0x00 0x1000 0x00 0x1100f000 0x00 0x10 0x00 0x10013000 0x00 0xbc >;
			interrupts = < 0x00 0xca 0x08 >;
			clocks = < 0x05 0x25 0x05 0x26 0x0b 0x2a 0x0b 0x2d 0x0b 0x2c 0x0b 0x2b >;
			clock-names = "cec_pdn\0clk_cec_26m\0mmsys_hdmi_pll\0mmsys_hdmi_pixel\0mmsys_hdmi_audio\0mmsys_hdmi_spidif";
			pinctrl-names = "default";
			pinctrl-0 = < 0x3e >;
			hdmi_power_control = < 0x0a 0x59 0x00 >;
		};

		disp_pwm0@14014000 {
			compatible = "mediatek,mt8163-disp_pwm";
			reg = < 0x00 0x14014000 0x00 0x1000 >;
		};

		mm_mutex@14015000 {
			compatible = "mediatek,mt8163-disp_mutex";
			reg = < 0x00 0x14015000 0x00 0x1000 >;
			interrupts = < 0x00 0xb1 0x08 >;
		};

		disp_wdma1@14018000 {
			compatible = "mediatek,mt8163-disp_wdma1";
			reg = < 0x00 0x14018000 0x00 0x1000 >;
			interrupts = < 0x00 0xc6 0x08 >;
		};

		disp_config2@10206000 {
			compatible = "mediatek,mt8163-disp_config2";
			reg = < 0x00 0x10206000 0x00 0x1000 >;
		};

		disp_config3@10000000 {
			compatible = "mediatek,mt8163-disp_config3";
			reg = < 0x00 0x10000000 0x00 0x1000 >;
		};

		disp_mipi@10215000 {
			compatible = "mediatek,mt8163-disp_mipi";
			reg = < 0x00 0x10215000 0x00 0x1000 >;
		};

		disp_io_driving@10005000 {
			compatible = "mediatek,mt8163-disp_io_driving";
			reg = < 0x00 0x10005000 0x00 0x1000 >;
		};

		disp_tvdpll_cfg6@100000a0 {
			compatible = "mediatek,mt8163-disp_tvdpll_cfg6";
			reg = < 0x00 0x100000a0 0x00 0x1000 >;
		};

		disp_tvdpll_con0@1000c270 {
			compatible = "mediatek,mt8163-disp_tvdpll_con0";
			reg = < 0x00 0x1000c270 0x00 0x1000 >;
		};

		disp_tvdpll_con1@1000c274 {
			compatible = "mediatek,mt8163-disp_tvdpll_con1";
			reg = < 0x00 0x1000c274 0x00 0x1000 >;
		};

		disp_lvds_ana@10215800 {
			compatible = "mediatek,mt8163-disp_lvds_ana";
			reg = < 0x00 0x10215800 0x00 0x1000 >;
		};

		g3d_iommu@13005000 {
			cell-index = < 0x02 >;
			compatible = "mediatek,mt8163-g3d_iommu";
			reg = < 0x00 0x13005000 0x00 0x1000 >;
			interrupts = < 0x00 0xe2 0x08 >;
		};

		larb@14016000 {
			compatible = "mediatek,mt8163-smi-larb";
			reg = < 0x00 0x14016000 0x00 0x1000 >;
			interrupts = < 0x00 0xcd 0x08 >;
			mediatek,smi = < 0x3f >;
			mediatek,larbid = < 0x00 >;
			clocks = < 0x0b 0x01 0x0b 0x01 >;
			clock-names = "apb\0smi";
			power-domains = < 0x2d 0x00 >;
		};

		smi@14017000 {
			compatible = "mediatek,mt8163-smi";
			reg = < 0x00 0x14017000 0x00 0x1000 >;
			clocks = < 0x0b 0x00 0x0b 0x00 >;
			clock-names = "apb\0smi";
			power-domains = < 0x2d 0x00 >;
			linux,phandle = < 0x3f >;
			phandle = < 0x3f >;
		};

		met_smi@14017000 {
			compatible = "mediatek,met_smi";
			reg = < 0x00 0x14017000 0x00 0x1000 0x00 0x14016000 0x00 0x1000 0x00 0x16010000 0x00 0x1000 0x00 0x15001000 0x00 0x1000 0x00 0x17001000 0x00 0x1000 >;
			clocks = < 0x0b 0x00 0x0b 0x01 0x40 0x00 0x41 0x00 0x42 0x01 >;
			clock-names = "smi-common\0smi-larb0\0vdec-larb1\0img-larb2\0venc-larb3";
		};

		disp_lvds_tx@1401b200 {
			compatible = "mediatek,mt8163-disp_lvds_tx";
			reg = < 0x00 0x1401b200 0x00 0x1000 >;
		};

		imgsys@15000000 {
			compatible = "mediatek,mt8163-imgsys\0syscon";
			reg = < 0x00 0x15000000 0x00 0x1000 >;
			#clock-cells = < 0x01 >;
			linux,phandle = < 0x41 >;
			phandle = < 0x41 >;
		};

		isp_display {
			compatible = "mediatek,mt8163-isp_display";
		};

		ispsys@15000000 {
			compatible = "mediatek,mt8163-ispsys";
			reg = < 0x00 0x15004000 0x00 0x9000 0x00 0x15000000 0x00 0x10000 0x00 0x10217000 0x00 0x3000 >;
			interrupts = < 0x00 0xda 0x08 0x00 0xdb 0x08 >;
			clocks = < 0x41 0x00 0x41 0x02 0x41 0x03 0x41 0x04 0x41 0x05 0x41 0x06 0x0b 0x00 >;
			clock-names = "IMG_LARB2_SMI\0IMG_CAM_SMI\0IMG_CAM_CAM\0IMG_SEN_TG\0IMG_SEN_CAM\0IMG_CAM_SV\0MM_SMI_COMMON";
		};

		larb@15001000 {
			compatible = "mediatek,mt8163-smi-larb";
			reg = < 0x00 0x15001000 0x00 0x1000 >;
			interrupts = < 0x00 0xd9 0x08 >;
			mediatek,smi = < 0x3f >;
			mediatek,larbid = < 0x02 >;
			clocks = < 0x41 0x00 0x41 0x00 >;
			clock-names = "apb\0smi";
			power-domains = < 0x2d 0x03 >;
		};

		camera1@15008000 {
			compatible = "mediatek,mt8163-camera_hw";
			reg = < 0x00 0x15008000 0x00 0x1000 >;
			clocks = < 0x06 0x47 0x06 0x36 0x06 0x39 >;
			clock-names = "TOP_CAMTG_SEL\0TOP_UNIVPLL_D26\0TOP_UNIVPLL2_D2";
			reg-vcama-supply = < 0x43 >;
			reg-vcamd-supply = < 0x44 >;
			reg-vcamio-supply = < 0x45 >;
			reg-vcamaf-supply = < 0x46 >;
			pinctrl-names = "default\0cam0_rst0\0cam0_rst1\0cam0_pnd0\0cam0_pnd1\0cam1_rst0\0cam1_rst1\0cam1_pnd0\0cam1_pnd1\0cam_ldo0_0\0cam_ldo0_1";
			pinctrl-0 = < 0x47 >;
			pinctrl-1 = < 0x48 >;
			pinctrl-2 = < 0x49 >;
			pinctrl-3 = < 0x4a >;
			pinctrl-4 = < 0x4b >;
			pinctrl-5 = < 0x4c >;
			pinctrl-6 = < 0x4d >;
			pinctrl-7 = < 0x4e >;
			pinctrl-8 = < 0x4f >;
			status = "okay";
		};

		camera2@15008000 {
			compatible = "mediatek,mt8163-camera_hw2";
			reg = < 0x00 0x15008000 0x00 0x1000 >;
			reg-vcama-supply = < 0x43 >;
			reg-vcamd-supply = < 0x44 >;
			reg-vcamio-supply = < 0x45 >;
			reg-vcamaf-supply = < 0x46 >;
		};

		vdecsys@16000000 {
			compatible = "mediatek,mt8163-vdecsys\0syscon";
			reg = < 0x00 0x16000000 0x00 0x1000 >;
			#clock-cells = < 0x01 >;
			linux,phandle = < 0x40 >;
			phandle = < 0x40 >;
		};

		vdec_gcon@16000000 {
			compatible = "mediatek,mt8163-vdec_gcon";
			reg = < 0x00 0x16000000 0x00 0x10000 >;
		};

		larb@16010000 {
			compatible = "mediatek,mt8163-smi-larb";
			reg = < 0x00 0x16010000 0x00 0x10000 >;
			interrupts = < 0x00 0xd5 0x08 >;
			mediatek,smi = < 0x3f >;
			mediatek,larbid = < 0x01 >;
			clocks = < 0x40 0x00 0x40 0x01 >;
			clock-names = "apb\0smi";
			power-domains = < 0x2d 0x01 >;
		};

		vdec@16020000 {
			compatible = "mediatek,mt8163-vdec";
			reg = < 0x00 0x16020000 0x00 0x10000 >;
			interrupts = < 0x00 0xd4 0x08 >;
		};

		vencsys@17000000 {
			compatible = "mediatek,mt8163-vencsys\0syscon";
			reg = < 0x00 0x17000000 0x00 0x1000 >;
			#clock-cells = < 0x01 >;
			linux,phandle = < 0x42 >;
			phandle = < 0x42 >;
		};

		larb@17001000 {
			compatible = "mediatek,mt8163-smi-larb";
			reg = < 0x00 0x17001000 0x00 0x1000 >;
			interrupts = < 0x00 0xcf 0x08 >;
			mediatek,smi = < 0x3f >;
			mediatek,larbid = < 0x03 >;
			clocks = < 0x42 0x01 0x42 0x00 >;
			clock-names = "apb\0smi";
			power-domains = < 0x2d 0x02 >;
		};

		venc@17002000 {
			compatible = "mediatek,mt8163-venc";
			reg = < 0x00 0x17002000 0x00 0x1000 >;
			interrupts = < 0x00 0xce 0x08 >;
		};

		jpgenc@17003000 {
			compatible = "mediatek,mt8163-jpgenc\0mediatek,jpgenc";
			reg = < 0x00 0x17003000 0x00 0x1000 >;
			interrupts = < 0x00 0xd0 0x08 >;
			clocks = < 0x42 0x02 >;
			clock-names = "venc-jpgenc";
		};

		btcvsd@18000000 {
			compatible = "mediatek,mt8163-audio_bt_cvsd\0mediatek,audio_bt_cvsd";
			offset = < 0xf00 0x800 0xfd0 0xfd4 0xfd8 >;
			reg = < 0x00 0x10001000 0x00 0x1000 0x00 0x18000000 0x00 0x10000 0x00 0x18080000 0x00 0x8000 >;
			interrupts = < 0x00 0xec 0x08 >;
		};

		consys@18070000 {
			compatible = "mediatek,mt8163-consys";
			reg = < 0x00 0x18070000 0x00 0x200 0x00 0x10001000 0x00 0x1000 >;
			power-domains = < 0x2d 0x04 >;
			interrupts = < 0x00 0xed 0x08 0x00 0xec 0x08 >;
			resets = < 0x50 0x0c >;
			reset-names = "connsys";
			status = "okay";
			pinctrl-names = "default\0gps_lna_state_init\0gps_lna_state_oh\0gps_lna_state_ol";
			pinctrl-0 = < 0x51 >;
			pinctrl-1 = < 0x52 >;
			pinctrl-2 = < 0x53 >;
			pinctrl-3 = < 0x54 >;
			vcn18-supply = < 0x55 >;
			vcn28-supply = < 0x56 >;
			vcn33_bt-supply = < 0x57 >;
			vcn33_wifi-supply = < 0x58 >;
		};

		wifi@180f0000 {
			compatible = "mediatek,wifi";
			reg = < 0x00 0x180f0000 0x00 0x5c >;
			interrupts = < 0x00 0xee 0x08 >;
			clocks = < 0x05 0x29 >;
			clock-names = "wifi-dma";
		};

		accdet@ {
			compatible = "mediatek,mt8163-accdet";
			status = "okay";
			interrupt-parent = < 0x0a >;
			interrupts = < 0x2d 0x08 >;
			eint-debounce = < 0x100 >;
			accdet-gpio = < 0x0a 0x22 0x00 >;
			accdet-mic-vol = < 0x07 >;
			headset-mode-setting = < 0x500 0x200 0x01 0x1f0 0x800 0x800 0x20 >;
			accdet-plugout-debounce = < 0x14 >;
			accdet-mic-mode = < 0x01 >;
			headset-three-key-threshold = < 0x00 0x50 0xdc 0x1f4 >;
			headset-four-key-threshold = < 0x00 0x3a 0x79 0xc0 0x1c2 >;
			pinctrl-names = "default\0state_eint_as_int";
			pinctrl-0 = < 0x59 >;
			pinctrl-1 = < 0x5a >;
		};

		touch@ {
			compatible = "mediatek,mt8163-touch";
			vtouch-supply = < 0x5b >;
			tpd-resolution = < 0x320 0x500 >;
			use-tpd-button = < 0x00 >;
			tpd-key-num = < 0x04 >;
			tpd-key-local = < 0x8b 0xac 0x9e 0x00 >;
			tpd-key-dim-local = < 0x3c 0x352 0x32 0x1e 0xb4 0x352 0x32 0x1e 0x12c 0x352 0x32 0x1e 0x1a4 0x352 0x32 0x1e >;
			tpd-max-touch-num = < 0x05 >;
			tpd-filter-enable = < 0x01 >;
			tpd-filter-pixel-density = < 0x7c >;
			tpd-filter-custom-prameters = < 0x00 0x00 0x00 0x00 0x00 0x00 0x00 0x00 0x00 0x00 0x00 0x00 >;
			tpd-filter-custom-speed = < 0x00 0x00 0x00 >;
			pinctrl-names = "default\0state_eint_as_int\0state_eint_output0\0state_eint_output1\0state_rst_output0\0state_rst_output1";
			pinctrl-0 = < 0x5c >;
			pinctrl-1 = < 0x5d >;
			pinctrl-2 = < 0x5e >;
			pinctrl-3 = < 0x5f >;
			pinctrl-4 = < 0x60 >;
			pinctrl-5 = < 0x61 >;
			status = "okay";
		};

		gps {
			compatible = "mediatek,gps";
		};

		hwmsensor@0 {
			compatible = "mediatek,hwmsensor";
		};

		gsensor@0 {
			compatible = "mediatek,gsensor";
		};

		als_ps@0 {
			compatible = "mediatek,als_ps";
		};

		batchsensor@0 {
			compatible = "mediatek,batchsensor";
		};

		gyroscope@0 {
			compatible = "mediatek,gyroscope";
		};

		barometer@0 {
			compatible = "mediatek,barometer";
		};

		msensor@0 {
			compatible = "mediatek,msensor";
		};

		orientation@0 {
			compatible = "mediatek,orientation";
		};

		led@0 {
			compatible = "mediatek,red";
			led_mode = < 0x03 >;
			data = < 0x08 >;
			pwm_config = < 0x00 0x00 0x00 0x00 0x00 >;
		};

		led@1 {
			compatible = "mediatek,green";
			led_mode = < 0x03 >;
			data = < 0x07 >;
			pwm_config = < 0x00 0x00 0x00 0x00 0x00 >;
		};

		led@2 {
			compatible = "mediatek,blue";
			led_mode = < 0x03 >;
			data = < 0x06 >;
			pwm_config = < 0x00 0x00 0x00 0x00 0x00 >;
		};

		led@3 {
			compatible = "mediatek,jogball-backlight";
			led_mode = < 0x00 >;
			data;
			pwm_config = < 0x00 0x00 0x00 0x00 0x00 >;
		};

		led@4 {
			compatible = "mediatek,keyboard-backlight";
			led_mode = < 0x00 >;
			data;
			pwm_config = < 0x00 0x00 0x00 0x00 0x00 >;
		};

		led@5 {
			compatible = "mediatek,button-backlight";
			led_mode = < 0x00 >;
			data;
			pwm_config = < 0x00 0x00 0x00 0x00 0x00 >;
		};

		led@6 {
			compatible = "mediatek,lcd-backlight";
			led_mode = < 0x05 >;
			data;
			pwm_config = < 0x00 0x00 0x00 0x00 0x00 >;
			gpios = < 0x0a 0x2b 0x00 >;
		};

		mtkfb@0 {
			compatible = "mediatek,MTKFB";
			clocks = < 0x0b 0x09 0x0b 0x0a 0x0b 0x0b 0x0b 0x0c 0x0b 0x0d 0x0b 0x0e 0x0b 0x17 0x0b 0x0f 0x0b 0x10 0x0b 0x11 0x0b 0x12 0x0b 0x13 0x0b 0x14 0x0b 0x20 0x0b 0x21 0x0b 0x22 0x0b 0x23 0x0b 0x24 0x0b 0x25 0x0b 0x26 0x0b 0x27 0x0b 0x28 0x0b 0x29 0x0b 0x2e 0x0b 0x2f 0x06 0x55 0x24 0x0a 0x06 0x14 0x06 0x15 0x06 0x16 0x06 0x59 0x24 0x06 0x06 0x2d 0x06 0x2e 0x06 0x2f 0x06 0x30 0x06 0x44 >;
			clock-names = "MMSYS_CLK_FAKE_ENG\0MMSYS_CLK_DISP_OVL0\0MMSYS_CLK_DISP_OVL1\0MMSYS_CLK_DISP_RDMA0\0MMSYS_CLK_DISP_RDMA1\0MMSYS_CLK_DISP_WDMA0\0MMSYS_CLK_DISP_WDMA1\0MMSYS_CLK_DISP_COLOR\0MMSYS_CLK_DISP_CCORR\0MMSYS_CLK_DISP_AAL\0MMSYS_CLK_DISP_GAMMA\0MMSYS_CLK_DISP_DITHER\0MMSYS_CLK_DISP_UFOE\0MMSYS_CLK_DISP_PWM\0MMSYS_CLK_DISP_PWM26M\0MMSYS_CLK_DSI_ENGINE\0MMSYS_CLK_DSI_DIGITAL\0MMSYS_CLK_DPI0_PIXEL\0MMSYS_CLK_DPI0_ENGINE\0MMSYS_CLK_LVDS_PIXEL\0MMSYS_CLK_LVDS_CTS\0MMSYS_CLK_DPI1_PIXEL\0MMSYS_CLK_DPI1_ENGINE\0MMSYS_CLK_DISP_DSC_ENGINE\0MMSYS_CLK_DISP_DSC_MEM\0MMSYS_CLK_MUX_DPI0_SEL\0MMSYS_APMIXED_LVDSPLL\0MMSYS_CLK_MUX_LVDSPLL_D2\0MMSYS_CLK_MUX_LVDSPLL_D4\0MMSYS_CLK_MUX_LVDSPLL_D8\0MMSYS_CLK_MUX_DPI1_SEL\0MMSYS_APMIXED_TVDPLL\0MMSYS_CLK_MUX_TVDPLL_D2\0MMSYS_CLK_MUX_TVDPLL_D4\0MMSYS_CLK_MUX_TVDPLL_D8\0MMSYS_CLK_MUX_TVDPLL_D16\0MMSYS_CLK_PWM_SEL";
		};

		bat_meter {
			compatible = "mediatek,bat_meter";
			r_bat_sense = < 0x04 >;
			r_i_sense = < 0x04 >;
			r_charger_1 = < 0x14a >;
			r_charger_2 = < 0x27 >;
			temperature_t0 = < 0x6e >;
			temperature_t1 = < 0x00 >;
			temperature_t2 = < 0x19 >;
			temperature_t3 = < 0x32 >;
			temperature_t = < 0xff >;
			fg_meter_resistance = < 0x00 >;
			q_max_pos_50 = < 0x1bb3 >;
			q_max_pos_25 = < 0x1bb3 >;
			q_max_pos_0 = < 0x1bb3 >;
			q_max_neg_10 = < 0x1bb3 >;
			q_max_pos_50_h_current = < 0x1853 >;
			q_max_pos_25_h_current = < 0x1853 >;
			q_max_pos_0_h_current = < 0x1853 >;
			q_max_neg_10_h_current = < 0x1853 >;
			oam_d5 = < 0x01 >;
			change_tracking_point = < 0x01 >;
			cust_tracking_point = < 0x0e >;
			cust_r_sense = < 0x38 >;
			cust_hw_cc = < 0x00 >;
			aging_tuning_value = < 0x64 >;
			cust_r_fg_offset = < 0x00 >;
			ocv_board_compesate = < 0x00 >;
			r_fg_board_base = < 0x3e8 >;
			r_fg_board_slope = < 0x3e8 >;
			car_tune_value = < 0x59 >;
			current_detect_r_fg = < 0x0a >;
			minerroroffset = < 0x3e8 >;
			fg_vbat_average_size = < 0x12 >;
			r_fg_value = < 0x14 >;
			cust_poweron_delta_capacity_tolrance = < 0x50 >;
			cust_poweron_low_capacity_tolrance = < 0x00 >;
			cust_poweron_max_vbat_tolrance = < 0x46 >;
			cust_poweron_delta_vbat_tolrance = < 0x3c >;
			cust_poweron_delta_hw_sw_ocv_capacity_tolrance = < 0x0a >;
			fixed_tbat_25 = < 0x01 >;
			vbat_normal_wakeup = < 0xe10 >;
			vbat_low_power_wakeup = < 0xdac >;
			normal_wakeup_period = < 0x1518 >;
			low_power_wakeup_period = < 0x12c >;
			close_poweroff_wakeup_period = < 0x1e >;
			rbat_pull_up_r = < 0x4204 >;
			rbat_pull_up_volt = < 0x708 >;
			batt_temperature_table_num = < 0x11 >;
			batt_temperature_table = < 0xffffffec 0x1250e 0xfffffff1 0xe246 0xfffffff6 0xb070 0xfffffffb 0x8adc 0x00 0x6e40 0x05 0x5843 0x0a 0x4737 0x0f 0x39e4 0x14 0x2f65 0x19 0x2710 0x1e 0x2067 0x23 0x1b0a 0x28 0x16b2 0x2d 0x1327 0x32 0x1040 0x37 0xddb 0x3c 0xbdf >;
			battery_profile_t0_num = < 0x58 >;
			battery_profile_t0 = < 0x00 0x105f 0x01 0x104f 0x02 0x1041 0x04 0x1035 0x05 0x1029 0x06 0x101d 0x07 0x1012 0x08 0x1007 0x09 0xffc 0x0b 0xff1 0x0c 0xfe7 0x0d 0xfde 0x0e 0xfd3 0x0f 0xfc9 0x11 0xfbf 0x12 0xfb6 0x13 0xfac 0x14 0xfa3 0x15 0xf9b 0x17 0xf92 0x18 0xf8a 0x19 0xf83 0x1a 0xf7b 0x1b 0xf73 0x1c 0xf6c 0x1e 0xf65 0x1f 0xf5e 0x20 0xf57 0x21 0xf50 0x22 0xf4a 0x24 0xf44 0x25 0xf3d 0x26 0xf36 0x27 0xf2e 0x28 0xf25 0x29 0xf1b 0x2b 0xf10 0x2c 0xf06 0x2d 0xefd 0x2e 0xef6 0x2f 0xef1 0x31 0xeeb 0x32 0xee7 0x33 0xee3 0x34 0xedf 0x35 0xedb 0x36 0xed8 0x38 0xed5 0x39 0xed2 0x3a 0xecf 0x3b 0xecc 0x3c 0xeca 0x3e 0xec8 0x3f 0xec6 0x40 0xec4 0x41 0xec2 0x42 0xec0 0x44 0xebf 0x45 0xebd 0x46 0xebc 0x47 0xebb 0x48 0xeb9 0x49 0xeb7 0x4b 0xeb4 0x4c 0xeb1 0x4d 0xeae 0x4e 0xeaa 0x4f 0xea5 0x51 0xea1 0x52 0xe9d 0x53 0xe99 0x54 0xe94 0x55 0xe8e 0x56 0xe86 0x58 0xe7f 0x59 0xe79 0x5a 0xe6f 0x5b 0xe65 0x5c 0xe61 0x5e 0xe5d 0x5f 0xe5a 0x60 0xe55 0x61 0xe4f 0x62 0xe45 0x64 0xe26 0x65 0xdf1 0x66 0xdaa 0x67 0xd47 >;
			battery_profile_t1_num = < 0x58 >;
			battery_profile_t1 = < 0x00 0x105f 0x01 0x104f 0x02 0x1041 0x04 0x1035 0x05 0x1029 0x06 0x101d 0x07 0x1012 0x08 0x1007 0x09 0xffc 0x0b 0xff1 0x0c 0xfe7 0x0d 0xfde 0x0e 0xfd3 0x0f 0xfc9 0x11 0xfbf 0x12 0xfb6 0x13 0xfac 0x14 0xfa3 0x15 0xf9b 0x17 0xf92 0x18 0xf8a 0x19 0xf83 0x1a 0xf7b 0x1b 0xf73 0x1c 0xf6c 0x1e 0xf65 0x1f 0xf5e 0x20 0xf57 0x21 0xf50 0x22 0xf4a 0x24 0xf44 0x25 0xf3d 0x26 0xf36 0x27 0xf2e 0x28 0xf25 0x29 0xf1b 0x2b 0xf10 0x2c 0xf06 0x2d 0xefd 0x2e 0xef6 0x2f 0xef1 0x31 0xeeb 0x32 0xee7 0x33 0xee3 0x34 0xedf 0x35 0xedb 0x36 0xed8 0x38 0xed5 0x39 0xed2 0x3a 0xecf 0x3b 0xecc 0x3c 0xeca 0x3e 0xec8 0x3f 0xec6 0x40 0xec4 0x41 0xec2 0x42 0xec0 0x44 0xebf 0x45 0xebd 0x46 0xebc 0x47 0xebb 0x48 0xeb9 0x49 0xeb7 0x4b 0xeb4 0x4c 0xeb1 0x4d 0xeae 0x4e 0xeaa 0x4f 0xea5 0x51 0xea1 0x52 0xe9d 0x53 0xe99 0x54 0xe94 0x55 0xe8e 0x56 0xe86 0x58 0xe7f 0x59 0xe79 0x5a 0xe6f 0x5b 0xe65 0x5c 0xe61 0x5e 0xe5d 0x5f 0xe5a 0x60 0xe55 0x61 0xe4f 0x62 0xe45 0x64 0xe26 0x65 0xdf1 0x66 0xdaa 0x67 0xd47 >;
			battery_profile_t2_num = < 0x58 >;
			battery_profile_t2 = < 0x00 0x105f 0x01 0x104f 0x02 0x1041 0x04 0x1035 0x05 0x1029 0x06 0x101d 0x07 0x1012 0x08 0x1007 0x09 0xffc 0x0b 0xff1 0x0c 0xfe7 0x0d 0xfde 0x0e 0xfd3 0x0f 0xfc9 0x11 0xfbf 0x12 0xfb6 0x13 0xfac 0x14 0xfa3 0x15 0xf9b 0x17 0xf92 0x18 0xf8a 0x19 0xf83 0x1a 0xf7b 0x1b 0xf73 0x1c 0xf6c 0x1e 0xf65 0x1f 0xf5e 0x20 0xf57 0x21 0xf50 0x22 0xf4a 0x24 0xf44 0x25 0xf3d 0x26 0xf36 0x27 0xf2e 0x28 0xf25 0x29 0xf1b 0x2b 0xf10 0x2c 0xf06 0x2d 0xefd 0x2e 0xef6 0x2f 0xef1 0x31 0xeeb 0x32 0xee7 0x33 0xee3 0x34 0xedf 0x35 0xedb 0x36 0xed8 0x38 0xed5 0x39 0xed2 0x3a 0xecf 0x3b 0xecc 0x3c 0xeca 0x3e 0xec8 0x3f 0xec6 0x40 0xec4 0x41 0xec2 0x42 0xec0 0x44 0xebf 0x45 0xebd 0x46 0xebc 0x47 0xebb 0x48 0xeb9 0x49 0xeb7 0x4b 0xeb4 0x4c 0xeb1 0x4d 0xeae 0x4e 0xeaa 0x4f 0xea5 0x51 0xea1 0x52 0xe9d 0x53 0xe99 0x54 0xe94 0x55 0xe8e 0x56 0xe86 0x58 0xe7f 0x59 0xe79 0x5a 0xe6f 0x5b 0xe65 0x5c 0xe61 0x5e 0xe5d 0x5f 0xe5a 0x60 0xe55 0x61 0xe4f 0x62 0xe45 0x64 0xe26 0x65 0xdf1 0x66 0xdaa 0x67 0xd47 >;
			battery_profile_t3_num = < 0x58 >;
			battery_profile_t3 = < 0x00 0x105f 0x01 0x104f 0x02 0x1041 0x04 0x1035 0x05 0x1029 0x06 0x101d 0x07 0x1012 0x08 0x1007 0x09 0xffc 0x0b 0xff1 0x0c 0xfe7 0x0d 0xfde 0x0e 0xfd3 0x0f 0xfc9 0x11 0xfbf 0x12 0xfb6 0x13 0xfac 0x14 0xfa3 0x15 0xf9b 0x17 0xf92 0x18 0xf8a 0x19 0xf83 0x1a 0xf7b 0x1b 0xf73 0x1c 0xf6c 0x1e 0xf65 0x1f 0xf5e 0x20 0xf57 0x21 0xf50 0x22 0xf4a 0x24 0xf44 0x25 0xf3d 0x26 0xf36 0x27 0xf2e 0x28 0xf25 0x29 0xf1b 0x2b 0xf10 0x2c 0xf06 0x2d 0xefd 0x2e 0xef6 0x2f 0xef1 0x31 0xeeb 0x32 0xee7 0x33 0xee3 0x34 0xedf 0x35 0xedb 0x36 0xed8 0x38 0xed5 0x39 0xed2 0x3a 0xecf 0x3b 0xecc 0x3c 0xeca 0x3e 0xec8 0x3f 0xec6 0x40 0xec4 0x41 0xec2 0x42 0xec0 0x44 0xebf 0x45 0xebd 0x46 0xebc 0x47 0xebb 0x48 0xeb9 0x49 0xeb7 0x4b 0xeb4 0x4c 0xeb1 0x4d 0xeae 0x4e 0xeaa 0x4f 0xea5 0x51 0xea1 0x52 0xe9d 0x53 0xe99 0x54 0xe94 0x55 0xe8e 0x56 0xe86 0x58 0xe7f 0x59 0xe79 0x5a 0xe6f 0x5b 0xe65 0x5c 0xe61 0x5e 0xe5d 0x5f 0xe5a 0x60 0xe55 0x61 0xe4f 0x62 0xe45 0x64 0xe26 0x65 0xdf1 0x66 0xdaa 0x67 0xd47 >;
			r_profile_t0_num = < 0x58 >;
			r_profile_t0 = < 0x76 0x105f 0x53 0x104f 0x53 0x1041 0x53 0x1035 0x53 0x1029 0x53 0x101d 0x54 0x1012 0x54 0x1007 0x55 0xffc 0x55 0xff1 0x56 0xfe7 0x58 0xfde 0x57 0xfd3 0x57 0xfc9 0x58 0xfbf 0x58 0xfb6 0x58 0xfac 0x58 0xfa3 0x5a 0xf9b 0x5a 0xf92 0x5a 0xf8a 0x5d 0xf83 0x5d 0xf7b 0x5d 0xf73 0x5b 0xf6c 0x5c 0xf65 0x5c 0xf5e 0x5d 0xf57 0x5d 0xf50 0x60 0xf4a 0x62 0xf44 0x63 0xf3d 0x64 0xf36 0x63 0xf2e 0x62 0xf25 0x5f 0xf1b 0x5c 0xf10 0x59 0xf06 0x57 0xefd 0x55 0xef6 0x56 0xef1 0x54 0xeeb 0x55 0xee7 0x54 0xee3 0x55 0xedf 0x54 0xedb 0x55 0xed8 0x56 0xed5 0x57 0xed2 0x56 0xecf 0x56 0xecc 0x58 0xeca 0x58 0xec8 0x58 0xec6 0x58 0xec4 0x58 0xec2 0x58 0xec0 0x58 0xebf 0x58 0xebd 0x59 0xebc 0x59 0xebb 0x59 0xeb9 0x5d 0xeb7 0x5d 0xeb4 0x5c 0xeb1 0x5c 0xeae 0x5b 0xeaa 0x5a 0xea5 0x5b 0xea1 0x5b 0xe9d 0x5c 0xe99 0x5d 0xe94 0x5d 0xe8e 0x5c 0xe86 0x5c 0xe7f 0x5d 0xe79 0x5c 0xe6f 0x5a 0xe65 0x5b 0xe61 0x5d 0xe5d 0x60 0xe5a 0x62 0xe55 0x67 0xe4f 0x6c 0xe45 0x6a 0xe26 0x6c 0xdf1 0x72 0xdaa 0x80 0xd47 >;
			r_profile_t1_num = < 0x58 >;
			r_profile_t1 = < 0x76 0x105f 0x53 0x104f 0x53 0x1041 0x53 0x1035 0x53 0x1029 0x53 0x101d 0x54 0x1012 0x54 0x1007 0x55 0xffc 0x55 0xff1 0x56 0xfe7 0x58 0xfde 0x57 0xfd3 0x57 0xfc9 0x58 0xfbf 0x58 0xfb6 0x58 0xfac 0x58 0xfa3 0x5a 0xf9b 0x5a 0xf92 0x5a 0xf8a 0x5d 0xf83 0x5d 0xf7b 0x5d 0xf73 0x5b 0xf6c 0x5c 0xf65 0x5c 0xf5e 0x5d 0xf57 0x5d 0xf50 0x60 0xf4a 0x62 0xf44 0x63 0xf3d 0x64 0xf36 0x63 0xf2e 0x62 0xf25 0x5f 0xf1b 0x5c 0xf10 0x59 0xf06 0x57 0xefd 0x55 0xef6 0x56 0xef1 0x54 0xeeb 0x55 0xee7 0x54 0xee3 0x55 0xedf 0x54 0xedb 0x55 0xed8 0x56 0xed5 0x57 0xed2 0x56 0xecf 0x56 0xecc 0x58 0xeca 0x58 0xec8 0x58 0xec6 0x58 0xec4 0x58 0xec2 0x58 0xec0 0x58 0xebf 0x58 0xebd 0x59 0xebc 0x59 0xebb 0x59 0xeb9 0x5d 0xeb7 0x5d 0xeb4 0x5c 0xeb1 0x5c 0xeae 0x5b 0xeaa 0x5a 0xea5 0x5b 0xea1 0x5b 0xe9d 0x5c 0xe99 0x5d 0xe94 0x5d 0xe8e 0x5c 0xe86 0x5c 0xe7f 0x5d 0xe79 0x5c 0xe6f 0x5a 0xe65 0x5b 0xe61 0x5d 0xe5d 0x60 0xe5a 0x62 0xe55 0x67 0xe4f 0x6c 0xe45 0x6a 0xe26 0x6c 0xdf1 0x72 0xdaa 0x80 0xd47 >;
			r_profile_t2_num = < 0x58 >;
			r_profile_t2 = < 0x76 0x105f 0x53 0x104f 0x53 0x1041 0x53 0x1035 0x53 0x1029 0x53 0x101d 0x54 0x1012 0x54 0x1007 0x55 0xffc 0x55 0xff1 0x56 0xfe7 0x58 0xfde 0x57 0xfd3 0x57 0xfc9 0x58 0xfbf 0x58 0xfb6 0x58 0xfac 0x58 0xfa3 0x5a 0xf9b 0x5a 0xf92 0x5a 0xf8a 0x5d 0xf83 0x5d 0xf7b 0x5d 0xf73 0x5b 0xf6c 0x5c 0xf65 0x5c 0xf5e 0x5d 0xf57 0x5d 0xf50 0x60 0xf4a 0x62 0xf44 0x63 0xf3d 0x64 0xf36 0x63 0xf2e 0x62 0xf25 0x5f 0xf1b 0x5c 0xf10 0x59 0xf06 0x57 0xefd 0x55 0xef6 0x56 0xef1 0x54 0xeeb 0x55 0xee7 0x54 0xee3 0x55 0xedf 0x54 0xedb 0x55 0xed8 0x56 0xed5 0x57 0xed2 0x56 0xecf 0x56 0xecc 0x58 0xeca 0x58 0xec8 0x58 0xec6 0x58 0xec4 0x58 0xec2 0x58 0xec0 0x58 0xebf 0x58 0xebd 0x59 0xebc 0x59 0xebb 0x59 0xeb9 0x5d 0xeb7 0x5d 0xeb4 0x5c 0xeb1 0x5c 0xeae 0x5b 0xeaa 0x5a 0xea5 0x5b 0xea1 0x5b 0xe9d 0x5c 0xe99 0x5d 0xe94 0x5d 0xe8e 0x5c 0xe86 0x5c 0xe7f 0x5d 0xe79 0x5c 0xe6f 0x5a 0xe65 0x5b 0xe61 0x5d 0xe5d 0x60 0xe5a 0x62 0xe55 0x67 0xe4f 0x6c 0xe45 0x6a 0xe26 0x6c 0xdf1 0x72 0xdaa 0x80 0xd47 >;
			r_profile_t3_num = < 0x58 >;
			r_profile_t3 = < 0x76 0x105f 0x53 0x104f 0x53 0x1041 0x53 0x1035 0x53 0x1029 0x53 0x101d 0x54 0x1012 0x54 0x1007 0x55 0xffc 0x55 0xff1 0x56 0xfe7 0x58 0xfde 0x57 0xfd3 0x57 0xfc9 0x58 0xfbf 0x58 0xfb6 0x58 0xfac 0x58 0xfa3 0x5a 0xf9b 0x5a 0xf92 0x5a 0xf8a 0x5d 0xf83 0x5d 0xf7b 0x5d 0xf73 0x5b 0xf6c 0x5c 0xf65 0x5c 0xf5e 0x5d 0xf57 0x5d 0xf50 0x60 0xf4a 0x62 0xf44 0x63 0xf3d 0x64 0xf36 0x63 0xf2e 0x62 0xf25 0x5f 0xf1b 0x5c 0xf10 0x59 0xf06 0x57 0xefd 0x55 0xef6 0x56 0xef1 0x54 0xeeb 0x55 0xee7 0x54 0xee3 0x55 0xedf 0x54 0xedb 0x55 0xed8 0x56 0xed5 0x57 0xed2 0x56 0xecf 0x56 0xecc 0x58 0xeca 0x58 0xec8 0x58 0xec6 0x58 0xec4 0x58 0xec2 0x58 0xec0 0x58 0xebf 0x58 0xebd 0x59 0xebc 0x59 0xebb 0x59 0xeb9 0x5d 0xeb7 0x5d 0xeb4 0x5c 0xeb1 0x5c 0xeae 0x5b 0xeaa 0x5a 0xea5 0x5b 0xea1 0x5b 0xe9d 0x5c 0xe99 0x5d 0xe94 0x5d 0xe8e 0x5c 0xe86 0x5c 0xe7f 0x5d 0xe79 0x5c 0xe6f 0x5a 0xe65 0x5b 0xe61 0x5d 0xe5d 0x60 0xe5a 0x62 0xe55 0x67 0xe4f 0x6c 0xe45 0x6a 0xe26 0x6c 0xdf1 0x72 0xdaa 0x80 0xd47 >;
		};

		BAT_NOTIFY {
			compatible = "mediatek,bat_notify";
		};

		bat_comm {
			compatible = "mediatek,battery";
			gpio22_dc_det = < 0x0a 0x16 0x00 >;
			gpio85_set_chr_set = < 0x0a 0x55 0x00 >;
			gpio28_spec_cur_select = < 0x0a 0x1c 0x00 >;
			stop_charging_in_takling = < 0x01 >;
			talking_recharge_voltage = < 0xed8 >;
			talking_sync_time = < 0x3c >;
			mtk_temperature_recharge_support = < 0x01 >;
			max_charge_temperature = < 0x32 >;
			max_charge_temperature_minus_x_degree = < 0x2f >;
			min_charge_temperature = < 0x00 >;
			min_charge_temperature_plus_x_degree = < 0x06 >;
			err_charge_temperature = < 0xff >;
			v_pre2cc_thres = < 0xd48 >;
			v_cc2topoff_thres = < 0xfd2 >;
			recharging_voltage = < 0x100e >;
			charging_full_current = < 0x50 >;
			config_usb_if = < 0x00 >;
			usb_charger_current_suspend = < 0x00 >;
			usb_charger_current_unconfigured = < 0x1b58 >;
			usb_charger_current_configured = < 0xc350 >;
			usb_charger_current = < 0xc350 >;
			ac_charger_current = < 0x222e0 >;
			non_std_ac_charger_current = < 0x222e0 >;
			charging_host_charger_current = < 0xfde8 >;
			apple_0_5a_charger_current = < 0xc350 >;
			apple_1_0a_charger_current = < 0xfde8 >;
			apple_2_1a_charger_current = < 0x13880 >;
			bat_low_temp_protect_enable = < 0x00 >;
			v_charger_enable = < 0x00 >;
			v_charger_max = < 0x1964 >;
			v_charger_min = < 0x1130 >;
			onehundred_percent_tracking_time = < 0x708 >;
			npercent_tracking_time = < 0xc8 >;
			sync_to_real_tracking_time = < 0x12c >;
			v_0percent_tracking = < 0xd8e >;
			high_battery_voltage_support = < 0x00 >;
		};

		dumchar {
			compatible = "mediatek,mt8163-dummy_char";
		};

		flashlight@ {
			compatible = "mediatek,camera_flashlight";
		};

		ice_debug {
			compatible = "mediatek,mt8163-ice_debug\0mediatek,mt8173-ice_debug";
			clocks = < 0x05 0x2f >;
			clock-names = "ice_dbg";
		};

		isp_pipemgr {
			compatible = "mediatek,mt8163-isp_pipemgr";
		};

		isp_sysram {
			compatible = "mediatek,mt8163-isp_sysram";
		};

		mtee {
			compatible = "mediatek,mtee";
		};
	};

	lcm {
		compatible = "mediatek,lcm";
		pinctrl-names = "default\0lcm_pwr_high\0lcm_pwr_low\0lcm_rst_high\0lcm_rst_low";
		pinctrl-0 = < 0x51 >;
		pinctrl-1 = < 0x62 >;
		pinctrl-2 = < 0x63 >;
		pinctrl-3 = < 0x64 >;
		pinctrl-4 = < 0x65 >;
		reg-lcm-supply = < 0x66 >;
		reg-lcm-vpa-supply = < 0x67 >;
		reg-lcm-vgp-vibr-supply = < 0x68 >;
	};

	lcm_kd {
		compatible = "mediatek,lcm_kd";
	};

	lcm_wy {
		compatible = "mediatek,lcm_wy";
	};

	memory@00000000 {
		device_type = "memory";
		reg = < 0x00 0x40000000 0x00 0x20000000 >;
	};

	chosen {
		bootargs = "console=ttyS0,921600n1 root=/dev/ram initrd=0x44000200,0x200000";
	};

	cust_accel@0 {
		compatible = "mediatek,STK8BAXX";
		i2c_num = < 0x02 >;
		i2c_addr = < 0x18 0x00 0x00 0x00 >;
		direction = < 0x0e >;
		power_id = < 0xffff >;
		power_vol = < 0x00 >;
		firlen = < 0x02 >;
		is_batch_supported = < 0x00 >;
	};

	cust_accel@1 {
		compatible = "mediatek,stk8312";
		i2c_num = < 0x02 >;
		i2c_addr = < 0x3d 0x00 0x00 0x00 >;
		direction = < 0x03 >;
		power_id = < 0xffff >;
		power_vol = < 0x00 >;
		firlen = < 0x02 >;
		is_batch_supported = < 0x00 >;
	};

	cust_gyro@0 {
		compatible = "mediatek,mpu6050gy";
		i2c_num = < 0x02 >;
		i2c_addr = < 0x68 0x00 0x00 0x00 >;
		direction = < 0x07 >;
		power_id = < 0xffff >;
		power_vol = < 0x00 >;
		firlen = < 0x00 >;
		is_batch_supported = < 0x00 >;
	};

	cust_mag@0 {
		compatible = "mediatek,akm09911";
		i2c_num = < 0x02 >;
		i2c_addr = < 0x0c 0x00 0x00 0x00 >;
		direction = < 0x06 >;
		power_id = < 0xffff >;
		power_vol = < 0x00 >;
		is_batch_supported = < 0x00 >;
	};

	mtcpufreq {
		compatible = "mediatek,mt8163-cpufreq";
		reg-ext-vproc-supply = < 0x69 >;
	};

	vibrator@0 {
		compatible = "mediatek,vibrator";
		vib_timer = < 0x19 >;
		vib_limit = < 0x09 >;
		vib_vol = < 0x05 >;
	};
};
